VERSION ""

NS_ :

BS_:

BU_: APS EPS ESP MPC MRR SCM GW

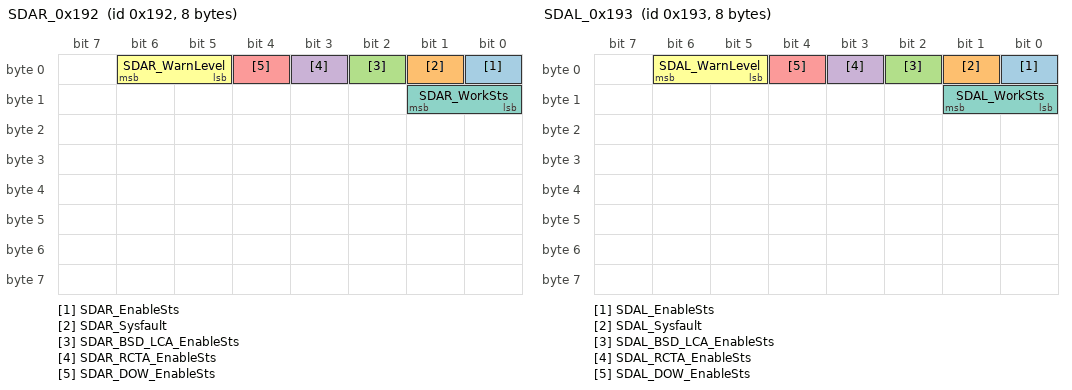
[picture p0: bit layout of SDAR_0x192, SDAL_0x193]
BO_ 402 SDAR_0x192: 8 GW
 SG_ SDAR_EnableSts : 0|1@0+ (1,0) [0|1] ""  APS
 SG_ SDAR_Sysfault : 1|1@0+ (1,0) [0|1] ""  APS
 SG_ SDAR_BSD_LCA_EnableSts : 2|1@0+ (1,0) [0|1] ""  APS
 SG_ SDAR_RCTA_EnableSts : 3|1@0+ (1,0) [0|1] ""  APS
 SG_ SDAR_DOW_EnableSts : 4|1@0+ (1,0) [0|1] ""  APS
 SG_ SDAR_WarnLevel : 6|2@0+ (1,0) [0|3] ""  APS
 SG_ SDAR_WorkSts : 9|2@0+ (1,0) [0|3] ""  APS

BO_ 403 SDAL_0x193: 8 GW
 SG_ SDAL_EnableSts : 0|1@0+ (1,0) [0|1] ""  APS
 SG_ SDAL_Sysfault : 1|1@0+ (1,0) [0|1] ""  APS
 SG_ SDAL_BSD_LCA_EnableSts : 2|1@0+ (1,0) [0|1] ""  APS
 SG_ SDAL_RCTA_EnableSts : 3|1@0+ (1,0) [0|1] ""  APS
 SG_ SDAL_DOW_EnableSts : 4|1@0+ (1,0) [0|1] ""  APS
 SG_ SDAL_WarnLevel : 6|2@0+ (1,0) [0|3] ""  APS
 SG_ SDAL_WorkSts : 9|2@0+ (1,0) [0|3] ""  APS

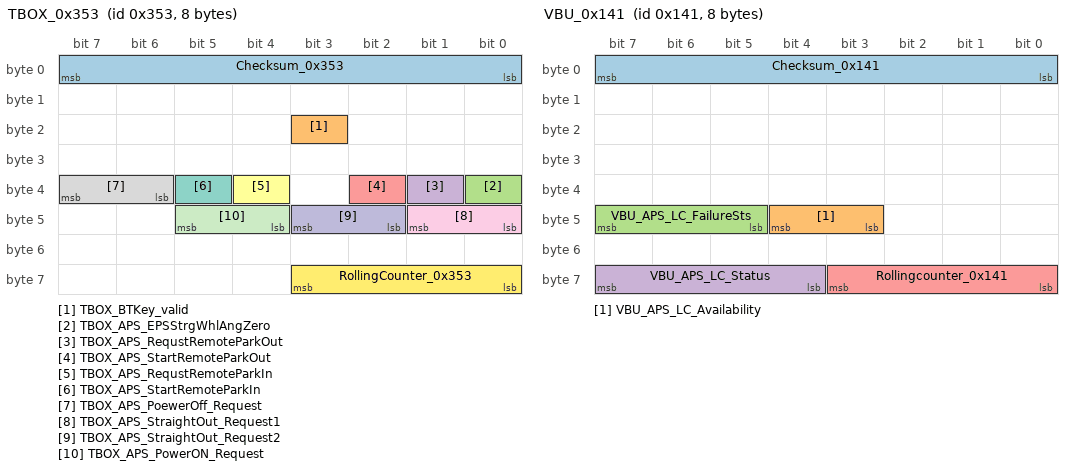
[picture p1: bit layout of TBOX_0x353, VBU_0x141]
BO_ 851 TBOX_0x353: 8 GW
 SG_ Checksum_0x353 : 7|8@0+ (1,0) [0|255] ""  APS
 SG_ TBOX_BTKey_valid : 19|1@0+ (1,0) [0|1] ""  APS
 SG_ TBOX_APS_EPSStrgWhlAngZero : 32|1@0+ (1,0) [0|1] ""  APS
 SG_ TBOX_APS_RequstRemoteParkOut : 33|1@0+ (1,0) [0|1] ""  APS
 SG_ TBOX_APS_StartRemoteParkOut : 34|1@0+ (1,0) [0|1] ""  APS
 SG_ TBOX_APS_RequstRemoteParkIn : 36|1@0+ (1,0) [0|1] ""  APS
 SG_ TBOX_APS_StartRemoteParkIn : 37|1@0+ (1,0) [0|1] ""  APS
 SG_ TBOX_APS_PoewerOff_Request : 39|2@0+ (1,0) [0|3] ""  APS
 SG_ TBOX_APS_StraightOut_Request1 : 41|2@0+ (1,0) [0|3] ""  APS
 SG_ TBOX_APS_StraightOut_Request2 : 43|2@0+ (1,0) [0|3] ""  APS
 SG_ TBOX_APS_PowerON_Request : 45|2@0+ (1,0) [0|3] ""  APS
 SG_ RollingCounter_0x353 : 59|4@0+ (1,0) [0|15] ""  APS

BO_ 289 ESP_0x121: 8 ESP
 SG_ Checksum_0x121 : 7|8@0+ (1,0) [0|255] ""  EPS,MPC,MRR,APS,GW
 SG_ ESP_VehicleSpeed : 11|12@0+ (0.05625,0) [0|230.2875] "kph"  EPS,MPC,MRR,APS,GW
 SG_ ESP_VehicleSpeed_Valid : 12|1@0+ (1,0) [0|1] ""  EPS,MPC,MRR,APS,GW
 SG_ ESP_ABS_Error : 14|1@0+ (1,0) [0|1] ""  EPS,MRR,APS,GW
 SG_ ESP_ABS_Intervention : 15|1@0+ (1,0) [0|1] ""  EPS,MPC,MRR,APS,GW
 SG_ ESP_VDC_TCS_Error : 24|1@0+ (1,0) [0|1] ""  MRR,APS,GW
 SG_ ESP_EBD_Error : 25|1@0+ (1,0) [0|1] ""  MRR,APS,GW
 SG_ ESP_VDC_Intervention : 26|1@0+ (1,0) [0|1] ""  MRR,APS,GW
 SG_ ESP_TCS_Intervention : 27|1@0+ (1,0) [0|1] ""  MRR,APS,GW
 SG_ ESP_EBD_Intervention : 28|1@0+ (1,0) [0|1] ""  MRR,APS,GW
 SG_ ESP_HDC_Available : 32|1@0+ (1,0) [0|1] ""  MRR,APS,GW
 SG_ ESP_EPBMainteDiagmodeActive : 33|1@0+ (1,0) [0|1] ""  MRR,APS,GW
 SG_ ESP_EPBStatus : 37|3@0+ (1,0) [0|7] ""  MRR,APS,GW
 SG_ ESP_VehicleStop : 38|1@0+ (1,0) [0|1] ""  MRR,APS,GW
 SG_ ESP_VehicleStop_Valid : 39|1@0+ (1,0) [0|1] ""  MRR,APS,GW
 SG_ ESP_WheelCyBrakeForce_Exist : 49|1@0+ (1,0) [0|1] ""  MRR,APS,GW
 SG_ ESP_HHC_Available : 54|1@0+ (1,0) [0|1] ""  APS,GW
 SG_ ESP_HHCActive : 55|1@0+ (1,0) [0|1] ""  APS,GW

BO_ 305 MRR_0x131: 8 MRR
 SG_ MRR_ACC_Status : 53|4@0+ (1,0) [0|15] ""  ESP,APS

BO_ 321 VBU_0x141: 8 GW
 SG_ Checksum_0x141 : 7|8@0+ (1,0) [0|255] ""  ESP,APS
 SG_ VBU_APS_LC_Availability : 44|2@0+ (1,0) [0|3] ""  APS
 SG_ VBU_APS_LC_FailureSts : 47|3@0+ (1,0) [0|7] ""  APS
 SG_ VBU_APS_LC_Status : 63|4@0+ (1,0) [0|15] ""  APS
 SG_ Rollingcounter_0x141 : 59|4@0+ (1,0) [0|15] ""  ESP,APS

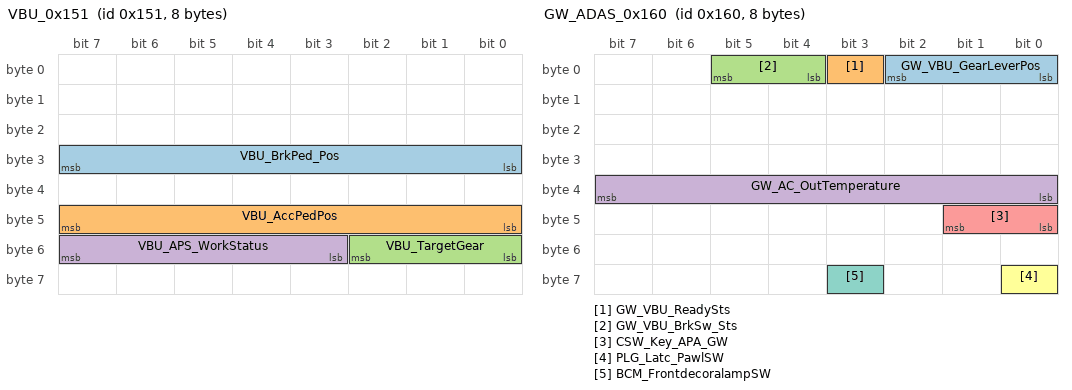
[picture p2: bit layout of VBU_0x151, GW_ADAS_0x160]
BO_ 337 VBU_0x151: 8 GW
 SG_ VBU_BrkPed_Pos : 31|8@0+ (1,0) [0|100] "%"  APS
 SG_ VBU_AccPedPos : 47|8@0+ (0.5,0) [0|100] "%"  ESP,MPC,MRR,APS
 SG_ VBU_TargetGear : 50|3@0+ (1,0) [0|7] ""  ESP,APS
 SG_ VBU_APS_WorkStatus : 55|5@0+ (1,0) [0|31] ""  APS

BO_ 341 GW_LIN_0x155: 8 GW
 SG_ SWS_L_360keyStatus : 11|2@0+ (1,0) [0|3] ""  APS

BO_ 352 GW_ADAS_0x160: 8 GW
 SG_ GW_VBU_GearLeverPos : 2|3@0+ (1,0) [0|7] ""  EPS,ESP,MPC,MRR,APS,SCM
 SG_ GW_VBU_ReadySts : 3|1@0+ (1,0) [0|1] ""  EPS,ESP,MPC,MRR,APS
 SG_ GW_VBU_BrkSw_Sts : 5|2@0+ (1,0) [0|3] ""  EPS,ESP,MPC,APS
 SG_ GW_AC_OutTemperature : 39|8@0+ (0.5,-40) [-40|80] "degC"  ESP,MPC,MRR,APS
 SG_ CSW_Key_APA_GW : 41|2@0+ (1,0) [0|3] ""  APS
 SG_ PLG_Latc_PawlSW : 56|1@0+ (1,0) [0|1] ""  APS
 SG_ BCM_FrontdecoralampSW : 59|1@0+ (1,0) [0|1] ""  APS

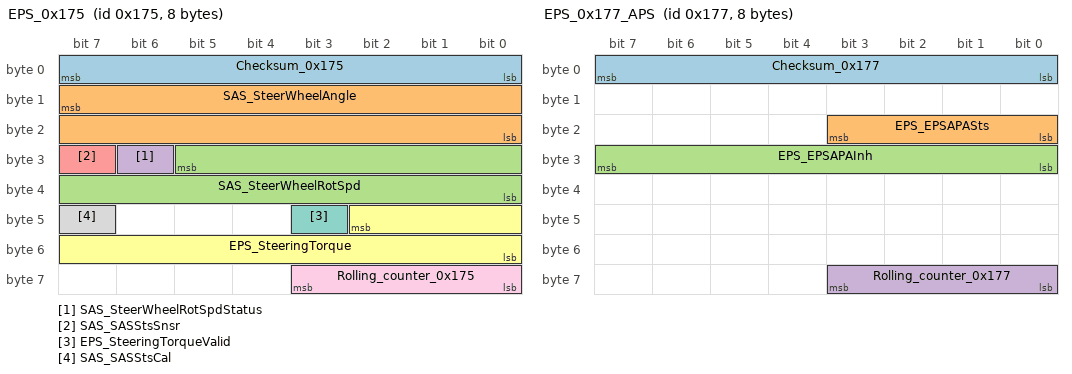
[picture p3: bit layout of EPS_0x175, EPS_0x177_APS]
BO_ 373 EPS_0x175: 8 EPS
 SG_ Checksum_0x175 : 7|8@0+ (1,0) [0|255] ""  ESP,MPC,MRR,APS,GW
 SG_ SAS_SteerWheelAngle : 15|16@0+ (0.0238,-780) [-780|779.733] "deg"  ESP,MPC,MRR,APS,GW
 SG_ SAS_SteerWheelRotSpd : 29|14@0+ (0.125,-1024) [-1024|1023.75] "degps"  MPC,MRR,APS,GW
 SG_ SAS_SteerWheelRotSpdStatus : 30|1@0+ (1,0) [0|1] ""  MPC,MRR,APS,GW
 SG_ SAS_SASStsSnsr : 31|1@0+ (1,0) [0|1] ""  ESP,MPC,MRR,APS,GW
 SG_ EPS_SteeringTorque : 42|11@0+ (0.01,-10.24) [-10.24|10.23] "Nm"  MPC,APS,GW
 SG_ EPS_SteeringTorqueValid : 43|1@0+ (1,0) [0|1] ""  MPC,APS,GW
 SG_ SAS_SASStsCal : 47|1@0+ (1,0) [0|1] ""  ESP,MPC,MRR,APS,GW
 SG_ Rolling_counter_0x175 : 59|4@0+ (1,0) [0|15] ""  ESP,MPC,MRR,APS,GW

BO_ 375 EPS_0x177_APS: 8 EPS
 SG_ Checksum_0x177 : 7|8@0+ (1,0) [0|255] ""  APS
 SG_ EPS_EPSAPASts : 19|4@0+ (1,0) [0|15] ""  APS
 SG_ EPS_EPSAPAInh : 31|8@0+ (1,0) [0|255] ""  APS
 SG_ Rolling_counter_0x177 : 59|4@0+ (1,0) [0|15] ""  APS

BO_ 401 APS_0x191: 8 APS
 SG_ Checksum_0x191 : 7|8@0+ (1,0) [0|255] ""  GW
 SG_ APS_SystemSts : 10|3@0+ (1,0) [0|7] ""  GW
 SG_ APS_Active : 11|1@0+ (1,0) [0|1] ""  MPC,MRR,GW
 SG_ APS_VBU_BrakeFunctionMode : 15|4@0+ (1,0) [0|15] ""  GW
 SG_ APS_VBU_Speed_Limitation : 23|6@0+ (0.8,0) [0|5] "kph"  GW
 SG_ APS_VBU_Target_Gear_Request : 26|3@0+ (1,0) [0|7] ""  GW
 SG_ APS_AVM_HU_CurrentSts : 29|3@0+ (1,0) [0|7] ""  GW
 SG_ APS_HU_ParkPrompttone : 30|1@0+ (1,0) [0|1] ""  GW
 SG_ APS_VBU_APAFailed : 31|1@0+ (1,0) [0|1] ""  GW
 SG_ APS_AVM_FactoryMode : 33|1@0+ (1,0) [0|1] ""  GW
 SG_ APS_TBOXConect_ParkInResp : 37|2@0+ (1,0) [0|3] ""  GW
 SG_ APS_VBU_FailureBrakeMode : 39|2@0+ (1,0) [0|3] ""  GW
 SG_ APS_VBU_Stop_Distance : 45|8@0+ (1,0) [0|255] ""  GW
 SG_ APS_R_Gear_RequestTips : 47|2@0+ (1,0) [0|3] ""  GW
 SG_ APS_VBU_Req_StraightOut : 48|1@0+ (1,0) [0|1] ""  GW
 SG_ APS_VBU_BrakeModeSts : 51|3@0+ (1,0) [0|7] ""  GW
 SG_ APS_VBU_Req_StraightCtrol : 53|2@0+ (1,0) [0|3] ""  GW
 SG_ RollingCounter_0x191 : 59|4@0+ (1,0) [0|15] ""  GW

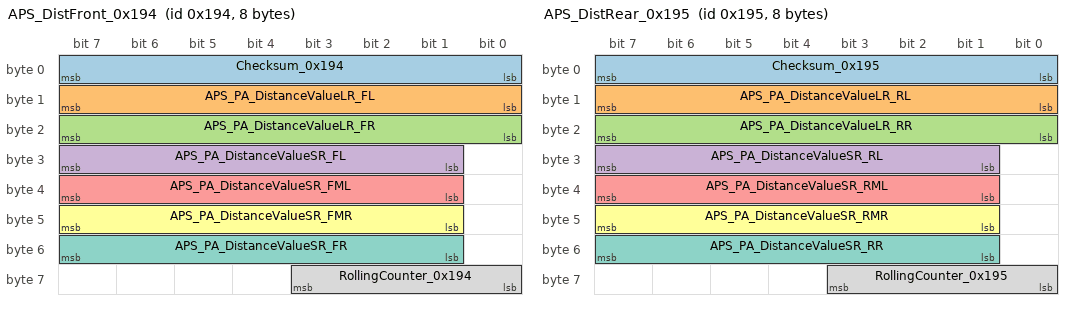
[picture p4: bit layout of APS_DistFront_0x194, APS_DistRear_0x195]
BO_ 404 APS_DistFront_0x194: 8 Vector__XXX
 SG_ Checksum_0x194 : 7|8@0+ (1,0) [0|255] "" Vector__XXX
 SG_ APS_PA_DistanceValueLR_FL : 15|8@0+ (2,0) [0|500] "cm" Vector__XXX
 SG_ APS_PA_DistanceValueLR_FR : 23|8@0+ (2,0) [0|500] "cm" Vector__XXX
 SG_ APS_PA_DistanceValueSR_FL : 31|7@0+ (2,0) [0|250] "cm" Vector__XXX
 SG_ APS_PA_DistanceValueSR_FML : 39|7@0+ (2,0) [0|250] "cm" Vector__XXX
 SG_ APS_PA_DistanceValueSR_FMR : 47|7@0+ (2,0) [0|250] "cm" Vector__XXX
 SG_ APS_PA_DistanceValueSR_FR : 55|7@0+ (2,0) [0|250] "cm" Vector__XXX
 SG_ RollingCounter_0x194 : 59|4@0+ (1,0) [0|15] "" Vector__XXX

BO_ 405 APS_DistRear_0x195: 8 Vector__XXX
 SG_ Checksum_0x195 : 7|8@0+ (1,0) [0|255] "" Vector__XXX
 SG_ APS_PA_DistanceValueLR_RL : 15|8@0+ (2,0) [0|500] "cm" Vector__XXX
 SG_ APS_PA_DistanceValueLR_RR : 23|8@0+ (2,0) [0|500] "cm" Vector__XXX
 SG_ APS_PA_DistanceValueSR_RL : 31|7@0+ (2,0) [0|250] "cm" Vector__XXX
 SG_ APS_PA_DistanceValueSR_RML : 39|7@0+ (2,0) [0|250] "cm" Vector__XXX
 SG_ APS_PA_DistanceValueSR_RMR : 47|7@0+ (2,0) [0|250] "cm" Vector__XXX
 SG_ APS_PA_DistanceValueSR_RR : 55|7@0+ (2,0) [0|250] "cm" Vector__XXX
 SG_ RollingCounter_0x195 : 59|4@0+ (1,0) [0|15] "" Vector__XXX

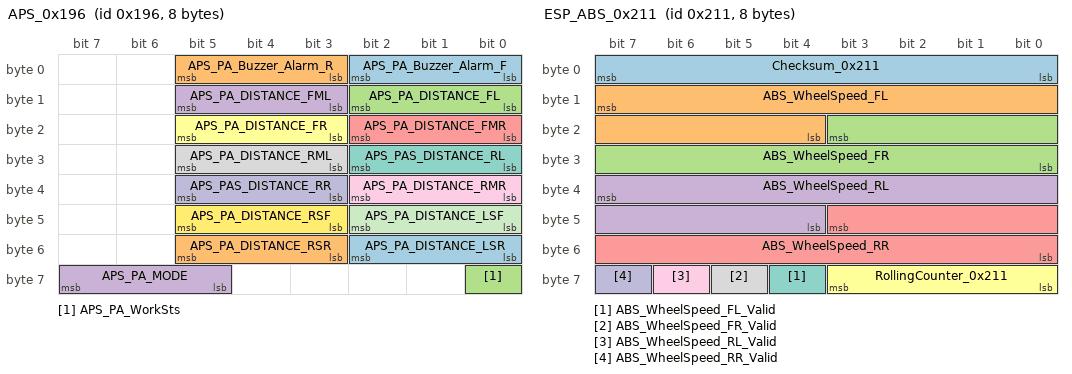
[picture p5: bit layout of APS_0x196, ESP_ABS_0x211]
BO_ 406 APS_0x196: 8 Vector__XXX
 SG_ APS_PA_Buzzer_Alarm_F : 2|3@0+ (1,0) [0|7] ""  GW
 SG_ APS_PA_Buzzer_Alarm_R : 5|3@0+ (1,0) [0|7] ""  GW
 SG_ APS_PA_DISTANCE_FL : 10|3@0+ (1,0) [0|7] ""  GW
 SG_ APS_PA_DISTANCE_FML : 13|3@0+ (1,0) [0|7] ""  GW
 SG_ APS_PA_DISTANCE_FMR : 18|3@0+ (1,0) [0|7] ""  GW
 SG_ APS_PA_DISTANCE_FR : 21|3@0+ (1,0) [0|7] ""  GW
 SG_ APS_PAS_DISTANCE_RL : 26|3@0+ (1,0) [0|7] ""  GW
 SG_ APS_PA_DISTANCE_RML : 29|3@0+ (1,0) [0|7] ""  GW
 SG_ APS_PA_DISTANCE_RMR : 34|3@0+ (1,0) [0|7] ""  GW
 SG_ APS_PAS_DISTANCE_RR : 37|3@0+ (1,0) [0|7] ""  GW
 SG_ APS_PA_DISTANCE_LSF : 42|3@0+ (1,0) [0|7] ""  GW
 SG_ APS_PA_DISTANCE_RSF : 45|3@0+ (1,0) [0|7] ""  GW
 SG_ APS_PA_DISTANCE_LSR : 50|3@0+ (1,0) [0|7] ""  GW
 SG_ APS_PA_DISTANCE_RSR : 53|3@0+ (1,0) [0|7] ""  GW
 SG_ APS_PA_WorkSts : 56|1@0+ (1,0) [0|1] ""  GW
 SG_ APS_PA_MODE : 63|3@0+ (1,0) [0|7] ""  GW

BO_ 529 ESP_ABS_0x211: 8 ESP
 SG_ Checksum_0x211 : 7|8@0+ (1,0) [0|255] ""  EPS,MRR,APS
 SG_ ABS_WheelSpeed_FL : 15|12@0+ (0.05625,0) [0|230.2875] "kph"  EPS,MRR,APS
 SG_ ABS_WheelSpeed_FR : 19|12@0+ (0.05625,0) [0|230.2875] "kph"  EPS,MRR,APS
 SG_ ABS_WheelSpeed_RL : 39|12@0+ (0.05625,0) [0|230.2875] "kph"  EPS,MRR,APS
 SG_ ABS_WheelSpeed_RR : 43|12@0+ (0.05625,0) [0|230.2875] "kph"  EPS,MRR,APS
 SG_ RollingCounter_0x211 : 59|4@0+ (1,0) [0|15] ""  EPS,MRR,APS
 SG_ ABS_WheelSpeed_FL_Valid : 60|1@0+ (1,0) [0|1] ""  EPS,MRR,APS
 SG_ ABS_WheelSpeed_FR_Valid : 61|1@0+ (1,0) [0|1] ""  EPS,MRR,APS
 SG_ ABS_WheelSpeed_RL_Valid : 62|1@0+ (1,0) [0|1] ""  EPS,MRR,APS
 SG_ ABS_WheelSpeed_RR_Valid : 63|1@0+ (1,0) [0|1] ""  EPS,MRR,APS

BO_ 532 ESP_0x214: 8 ESP
 SG_ Checksum_0x214 : 7|8@0+ (1,0) [0|255] ""  MRR,APS
 SG_ ESP_WheelDirection_FL : 9|2@0+ (1,0) [0|3] ""  MRR,APS
 SG_ ESP_WheelDirection_FL_Valid : 10|1@0+ (1,0) [0|1] ""  MRR,APS
 SG_ ESP_WheelDirection_FR : 12|2@0+ (1,0) [0|3] ""  MRR,APS
 SG_ ESP_WheelDirection_FR_Valid : 13|1@0+ (1,0) [0|1] ""  MRR,APS
 SG_ ESP_WheelDirection_RL : 15|2@0+ (1,0) [0|3] ""  MRR,APS
 SG_ ESP_WheelDirection_RL_Valid : 16|1@0+ (1,0) [0|1] ""  MRR,APS
 SG_ ESP_WheelDirection_RR : 18|2@0+ (1,0) [0|3] ""  MRR,APS
 SG_ ESP_WheelDirection_RR_Valid : 19|1@0+ (1,0) [0|1] ""  MRR,APS
 SG_ ESP_CDD_Intervention : 20|1@0+ (1,0) [0|1] ""  MRR,APS
 SG_ ESP_CDD_Available : 21|1@0+ (1,0) [0|1] ""  MRR,APS
 SG_ ESP_CDD_Error : 22|1@0+ (1,0) [0|1] ""  MRR,APS
 SG_ ESP_CDDTempOff : 23|1@0+ (1,0) [0|1] ""  MRR,APS
 SG_ ESP_VLC_EngTrqReq : 46|15@0+ (0.1,-1000) [-1000|1000] "Nm"  APS
 SG_ ESP_VLC_EngTrqReqActive : 47|1@0+ (1,0) [0|1] ""  APS
 SG_ RollingCounter_0x214 : 59|4@0+ (1,0) [0|15] ""  MRR,APS
 SG_ ESP_VLC_Intervention : 60|1@0+ (1,0) [0|1] ""  MRR,APS
 SG_ ESP_VLC_Error : 61|1@0+ (1,0) [0|1] ""  MRR,APS
 SG_ ESP_VLC_Available : 62|1@0+ (1,0) [0|1] ""  MRR,APS

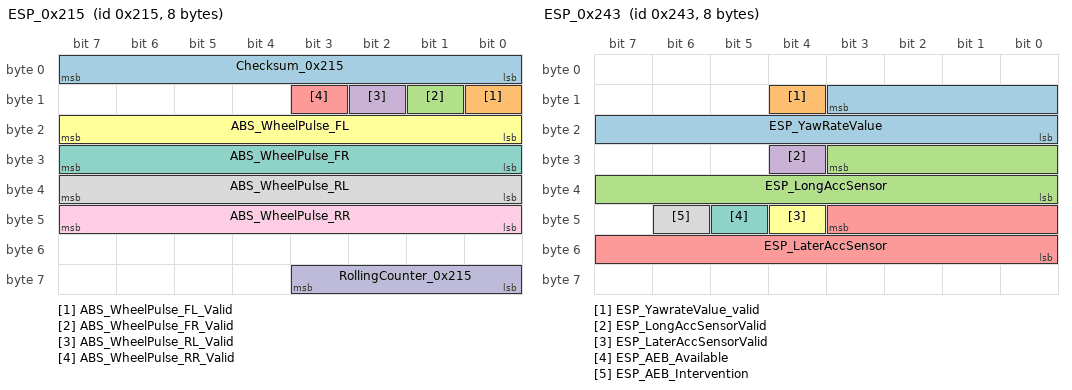
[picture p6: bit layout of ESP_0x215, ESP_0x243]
BO_ 533 ESP_0x215: 8 ESP
 SG_ Checksum_0x215 : 7|8@0+ (1,0) [0|255] ""  APS
 SG_ ABS_WheelPulse_FL_Valid : 8|1@0+ (1,0) [0|1] ""  APS
 SG_ ABS_WheelPulse_FR_Valid : 9|1@0+ (1,0) [0|1] ""  APS
 SG_ ABS_WheelPulse_RL_Valid : 10|1@0+ (1,0) [0|1] ""  APS
 SG_ ABS_WheelPulse_RR_Valid : 11|1@0+ (1,0) [0|1] ""  APS
 SG_ ABS_WheelPulse_FL : 23|8@0+ (1,0) [0|255] ""  APS
 SG_ ABS_WheelPulse_FR : 31|8@0+ (1,0) [0|255] ""  APS
 SG_ ABS_WheelPulse_RL : 39|8@0+ (1,0) [0|255] ""  APS
 SG_ ABS_WheelPulse_RR : 47|8@0+ (1,0) [0|255] ""  APS
 SG_ RollingCounter_0x215 : 59|4@0+ (1,0) [0|15] ""  APS

BO_ 579 ESP_0x243: 8 ESP
 SG_ ESP_YawRateValue : 11|12@0+ (0.05,-75) [-75|75] "deg"  MPC,MRR,APS,GW
 SG_ ESP_YawrateValue_valid : 12|1@0+ (1,0) [0|1] ""  MPC,MRR,APS,GW
 SG_ ESP_LongAccSensor : 27|12@0+ (0.01,-20) [-20|20] "mps2"  MPC,MRR,APS,GW
 SG_ ESP_LongAccSensorValid : 28|1@0+ (1,0) [0|1] ""  MPC,MRR,APS,GW
 SG_ ESP_LaterAccSensor : 43|12@0+ (0.01,-20) [-20|20] "mps2"  MPC,MRR,APS,GW
 SG_ ESP_LaterAccSensorValid : 44|1@0+ (1,0) [0|1] ""  MPC,MRR,APS,GW
 SG_ ESP_AEB_Available : 45|1@0+ (1,0) [0|1] ""  MRR,APS,GW
 SG_ ESP_AEB_Intervention : 46|1@0+ (1,0) [0|1] ""  MRR,APS,GW

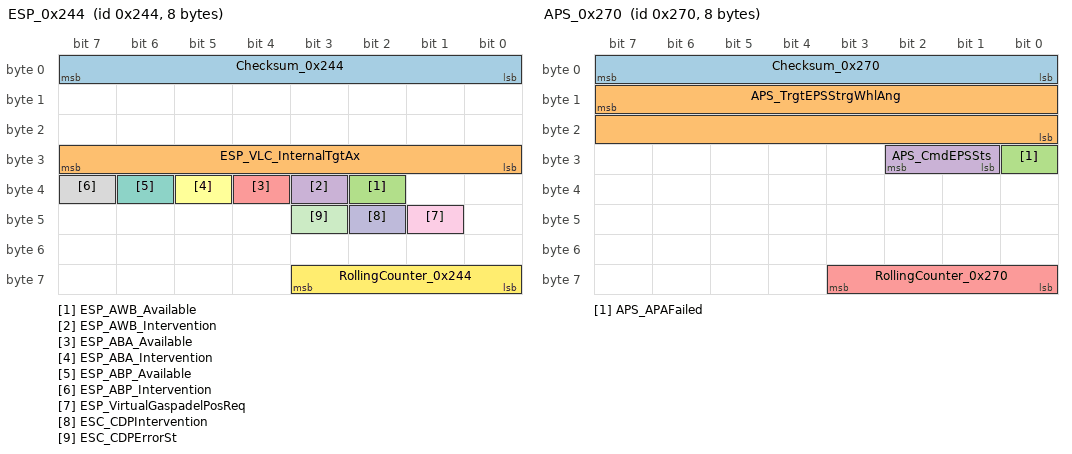
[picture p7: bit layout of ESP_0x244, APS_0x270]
BO_ 580 ESP_0x244: 8 ESP
 SG_ Checksum_0x244 : 7|8@0+ (1,0) [0|255] ""  MRR,APS
 SG_ ESP_VLC_InternalTgtAx : 31|8@0+ (0.05,-7) [-7|5.75] "mps2"  MRR,APS
 SG_ ESP_AWB_Available : 34|1@0+ (1,0) [0|1] ""  MRR,APS
 SG_ ESP_AWB_Intervention : 35|1@0+ (1,0) [0|1] ""  MRR,APS
 SG_ ESP_ABA_Available : 36|1@0+ (1,0) [0|1] ""  MRR,APS
 SG_ ESP_ABA_Intervention : 37|1@0+ (1,0) [0|1] ""  MRR,APS
 SG_ ESP_ABP_Available : 38|1@0+ (1,0) [0|1] ""  MRR,APS
 SG_ ESP_ABP_Intervention : 39|1@0+ (1,0) [0|1] ""  MRR,APS
 SG_ ESP_VirtualGaspadelPosReq : 41|1@0+ (1,0) [0|1] ""  APS
 SG_ ESC_CDPIntervention : 42|1@0+ (1,0) [0|1] ""  MRR,APS
 SG_ ESC_CDPErrorSt : 43|1@0+ (1,0) [0|1] ""  APS
 SG_ RollingCounter_0x244 : 59|4@0+ (1,0) [0|15] ""  MRR,APS

BO_ 624 APS_0x270: 8 APS
 SG_ Checksum_0x270 : 7|8@0+ (1,0) [0|255] ""  EPS
 SG_ APS_TrgtEPSStrgWhlAng : 15|16@0+ (0.0238,-780) [-780|779.733] "deg"  EPS
 SG_ APS_APAFailed : 24|1@0+ (1,0) [0|1] ""  EPS
 SG_ APS_CmdEPSSts : 26|2@0+ (1,0) [0|3] ""  EPS
 SG_ RollingCounter_0x270 : 59|4@0+ (1,0) [0|15] ""  EPS

BO_ 625 APS_0x271: 8 APS
 SG_ Checksum_0x271 : 7|8@0+ (1,0) [0|255] ""  GW
 SG_ APS_AutoSearchSts : 10|3@0+ (1,0) [0|7] ""  GW
 SG_ APS_ParkOutChkResult : 11|1@0+ (1,0) [0|1] ""  GW
 SG_ APS_CurrentPathNum : 15|4@0+ (1,0) [0|15] ""  GW
 SG_ APS_TotalPathNum : 19|4@0+ (1,0) [0|15] ""  GW
 SG_ APS_SuspendedReason : 22|3@0+ (1,0) [0|7] ""  GW
 SG_ APS_AbortReason : 28|5@0+ (1,0) [0|31] ""  GW
 SG_ APS_CurrentParkType : 31|3@0+ (1,0) [0|7] ""  GW
 SG_ APS_OverrideReason : 34|3@0+ (1,0) [0|7] ""  GW
 SG_ APS_VehicleDirection : 36|2@0+ (1,0) [0|3] ""  GW
 SG_ APS_TerminatedType : 38|2@0+ (1,0) [0|3] ""  GW
 SG_ APS_ParkOutSystemStatus : 39|1@0+ (1,0) [0|1] ""  GW
 SG_ APS_CurrentStepNum : 43|4@0+ (1,0) [0|15] ""  GW
 SG_ APS_RemoteParkIn_Status : 46|3@0+ (1,0) [0|7] ""  GW
 SG_ APS_RemoteParkInResp : 47|1@0+ (1,0) [0|1] ""  GW
 SG_ APS_BCM_RemoteParkIn_Status : 48|1@0+ (1,0) [0|1] ""  GW
 SG_ APS_BCM_DoubleFlash : 49|1@0+ (1,0) [0|1] ""  GW
 SG_ APS_BCM_AllDoorUnLock_Door : 50|1@0+ (1,0) [0|1] ""  GW
 SG_ APS_RemoteParkOutResp : 51|1@0+ (1,0) [0|1] ""  GW
 SG_ APS_BCM_PowerOffReq : 52|1@0+ (1,0) [0|1] ""  GW
 SG_ APS_RemotePark_Error_Status : 55|3@0+ (1,0) [0|7] ""  GW
 SG_ RollingCounter_0x271 : 59|4@0+ (1,0) [0|15] ""  GW

BO_ 642 SCM_0x282: 8 SCM
 SG_ SCM_PRND_req : 34|3@0+ (1,0) [0|7] ""  APS,GW

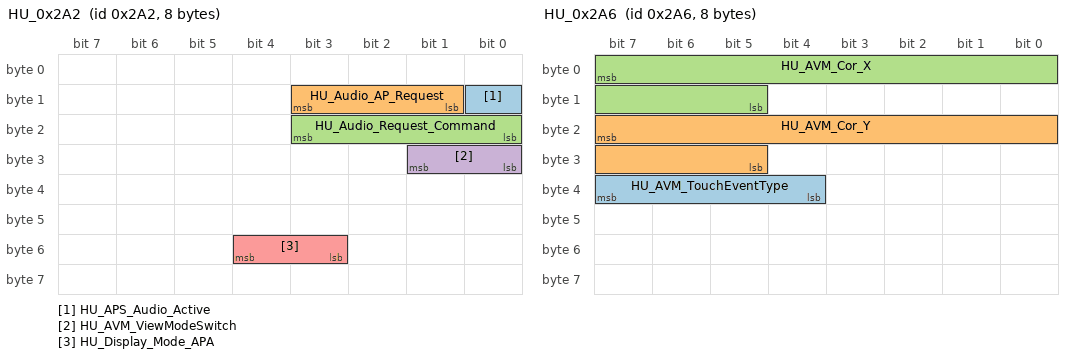
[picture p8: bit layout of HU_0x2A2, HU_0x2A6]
BO_ 674 HU_0x2A2: 8 GW
 SG_ HU_APS_Audio_Active : 8|1@0+ (1,0) [0|1] ""  APS
 SG_ HU_Audio_AP_Request : 11|3@0+ (1,0) [0|7] ""  APS
 SG_ HU_Audio_Request_Command : 19|4@0+ (1,0) [0|15] ""  APS
 SG_ HU_AVM_ViewModeSwitch : 25|2@0+ (1,0) [0|3] ""  APS
 SG_ HU_Display_Mode_APA : 52|2@0+ (1,0) [0|3] ""  APS

BO_ 678 HU_0x2A6: 8 GW
 SG_ HU_AVM_TouchEventType : 39|4@0+ (1,0) [0|15] ""  APS
 SG_ HU_AVM_Cor_Y : 23|11@0+ (1,0) [0|2047] ""  APS
 SG_ HU_AVM_Cor_X : 7|11@0+ (1,0) [0|2047] ""  APS

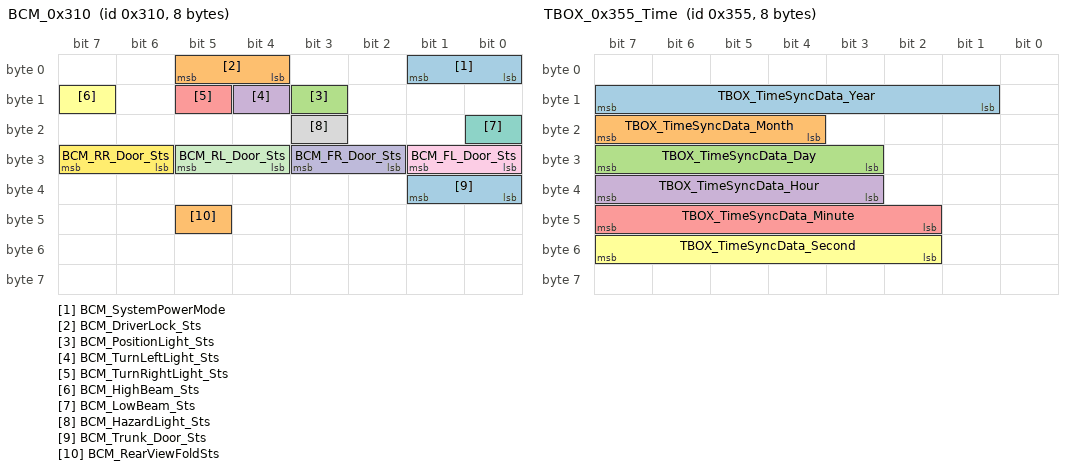
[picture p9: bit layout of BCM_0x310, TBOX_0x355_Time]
BO_ 784 BCM_0x310: 8 GW
 SG_ BCM_SystemPowerMode : 1|2@0+ (1,0) [0|3] ""  ESP,MPC,MRR,APS
 SG_ BCM_DriverLock_Sts : 5|2@0+ (1,0) [0|3] ""  APS
 SG_ BCM_PositionLight_Sts : 11|1@0+ (1,0) [0|1] ""  APS
 SG_ BCM_TurnLeftLight_Sts : 12|1@0+ (1,0) [0|1] ""  MPC,APS
 SG_ BCM_TurnRightLight_Sts : 13|1@0+ (1,0) [0|1] ""  MPC,APS
 SG_ BCM_HighBeam_Sts : 15|1@0+ (1,0) [0|1] ""  MPC,APS
 SG_ BCM_LowBeam_Sts : 16|1@0+ (1,0) [0|1] ""  MPC,APS
 SG_ BCM_HazardLight_Sts : 19|1@0+ (1,0) [0|1] ""  MPC,APS
 SG_ BCM_FL_Door_Sts : 25|2@0+ (1,0) [0|3] ""  ESP,MRR,APS
 SG_ BCM_FR_Door_Sts : 27|2@0+ (1,0) [0|3] ""  MRR,APS
 SG_ BCM_RL_Door_Sts : 29|2@0+ (1,0) [0|3] ""  MRR,APS
 SG_ BCM_RR_Door_Sts : 31|2@0+ (1,0) [0|3] ""  MRR,APS
 SG_ BCM_Trunk_Door_Sts : 33|2@0+ (1,0) [0|3] ""  APS
 SG_ BCM_RearViewFoldSts : 45|1@0+ (1,0) [0|1] ""  APS

BO_ 853 TBOX_0x355_Time: 8 GW
 SG_ TBOX_TimeSyncData_Year : 15|7@0+ (1,2000) [2000|2099] ""  EPS,ESP,MPC,MRR,APS
 SG_ TBOX_TimeSyncData_Month : 23|4@0+ (1,0) [1|12] ""  EPS,ESP,MPC,MRR,APS
 SG_ TBOX_TimeSyncData_Day : 31|5@0+ (1,0) [1|31] ""  EPS,ESP,MPC,MRR,APS
 SG_ TBOX_TimeSyncData_Hour : 39|5@0+ (1,0) [0|23] ""  EPS,ESP,MPC,MRR,APS
 SG_ TBOX_TimeSyncData_Minute : 47|6@0+ (1,0) [0|59] ""  EPS,ESP,MPC,MRR,APS
 SG_ TBOX_TimeSyncData_Second : 55|6@0+ (1,0) [0|59] ""  EPS,ESP,MPC,MRR,APS

BO_ 928 ICM_0x3A0: 8 GW
 SG_ ICM_DisPlayVehicleSpeed : 27|12@0+ (0.05625,0) [0|230.2875] "kph"  MPC,MRR,APS

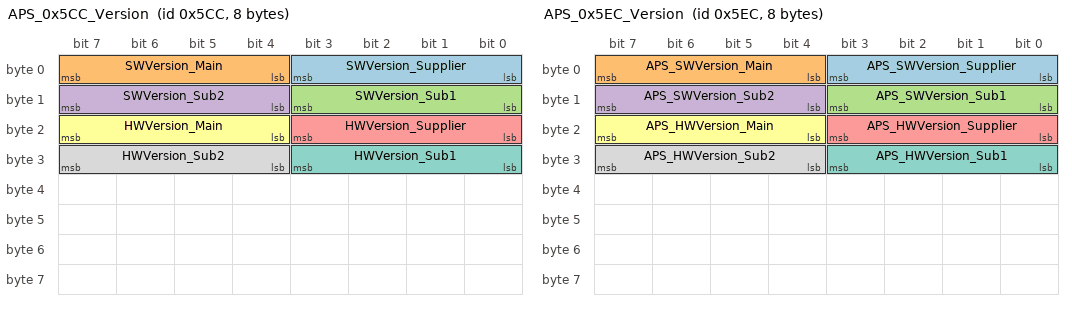
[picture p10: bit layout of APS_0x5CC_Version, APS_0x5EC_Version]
BO_ 1484 APS_0x5CC_Version: 8 Vector__XXX
 SG_ SWVersion_Supplier : 3|4@0+ (1,0) [0|15] ""  GW
 SG_ SWVersion_Main : 7|4@0+ (1,0) [0|15] ""  GW
 SG_ SWVersion_Sub1 : 11|4@0+ (1,0) [0|15] ""  GW
 SG_ SWVersion_Sub2 : 15|4@0+ (1,0) [0|15] ""  GW
 SG_ HWVersion_Supplier : 19|4@0+ (1,0) [0|15] ""  GW
 SG_ HWVersion_Main : 23|4@0+ (1,0) [0|15] ""  GW
 SG_ HWVersion_Sub1 : 27|4@0+ (1,0) [0|15] ""  GW
 SG_ HWVersion_Sub2 : 31|4@0+ (1,0) [0|15] ""  GW

BO_ 1516 APS_0x5EC_Version: 8 APS
 SG_ APS_SWVersion_Supplier : 3|4@0+ (1,0) [0|15] ""  GW
 SG_ APS_SWVersion_Main : 7|4@0+ (1,0) [0|15] ""  GW
 SG_ APS_SWVersion_Sub1 : 11|4@0+ (1,0) [0|15] ""  GW
 SG_ APS_SWVersion_Sub2 : 15|4@0+ (1,0) [0|15] ""  GW
 SG_ APS_HWVersion_Supplier : 19|4@0+ (1,0) [0|15] ""  GW
 SG_ APS_HWVersion_Main : 23|4@0+ (1,0) [0|15] ""  GW
 SG_ APS_HWVersion_Sub1 : 27|4@0+ (1,0) [0|15] ""  GW
 SG_ APS_HWVersion_Sub2 : 31|4@0+ (1,0) [0|15] ""  GW

BO_ 1829 APS_UDSDiag_ReqPhsy: 8 GW
 SG_ APS_UDSDiag_ReqPhsy_0x725 : 7|64@0+ (1,0) [0|255] "" Vector__XXX

BO_ 1837 APS_UDSDiag_Resp: 8 Vector__XXX
 SG_ APS_UDSDiag_Resp_0x72D : 7|64@0+ (1,0) [0|255] ""  GW

BO_ 2015 UDSDiag_ReqFunc: 8 GW
 SG_ UDSDiag_ReqFunc_0x7DF : 7|64@0+ (1,0) [0|255] ""  EPS,ESP,MPC,MRR,SCM

BO_ 1841 PA_UDSDiag_ReqPhsy: 8 GW
 SG_ PA_UDSDiag_ReqPhsy_0x731 : 7|64@0+ (1,0) [0|255] "" Vector__XXX

BO_ 1849 PA_UDSDiag_Resp: 8 Vector__XXX
 SG_ PA_UDSDiag_Resp_0x739 : 7|64@0+ (1,0) [0|255] ""  GW

CM_ SG_ 402 SDAR_EnableSts "右雷达使能状态";
CM_ SG_ 402 SDAR_Sysfault "右雷达系统错误";
CM_ SG_ 402 SDAR_BSD_LCA_EnableSts "BSD/LCA功能使能状态";
CM_ SG_ 402 SDAR_RCTA_EnableSts "RCTA功能使能状态";
CM_ SG_ 402 SDAR_DOW_EnableSts "DOW功能使能状态";
CM_ SG_ 402 SDAR_WarnLevel "右雷达报警等级";
CM_ SG_ 402 SDAR_WorkSts "右雷达工作状态";
CM_ SG_ 403 SDAL_EnableSts "左雷达使能状态";
CM_ SG_ 403 SDAL_Sysfault "左雷达系统错误";
CM_ SG_ 403 SDAL_BSD_LCA_EnableSts "BSD/LCA功能使能状态";
CM_ SG_ 403 SDAL_RCTA_EnableSts "RCTA功能使能状态";
CM_ SG_ 403 SDAL_DOW_EnableSts "DOW功能使能状态";
CM_ SG_ 403 SDAL_WarnLevel "左雷达报警等级";
CM_ SG_ 403 SDAL_WorkSts "左雷达工作状态";
CM_ SG_ 851 Checksum_0x353 "Checksum: IDMSB XOR IDLSB XOR Byte1 XOR Byte2 XOR Byte3 XOR Byte4 XOR Byte5 XOR Byte6 XOR Byte7";
CM_ SG_ 851 TBOX_BTKey_valid "TBOX蓝牙钥匙连接状态";
CM_ SG_ 851 TBOX_APS_EPSStrgWhlAngZero "一键回正方向盘信号";
CM_ SG_ 851 TBOX_APS_RequstRemoteParkOut "TBOX允许遥控泊出指令";
CM_ SG_ 851 TBOX_APS_StartRemoteParkOut "按下APP遥控泊出按键状态";
CM_ SG_ 851 TBOX_APS_RequstRemoteParkIn "TBOX允许遥控泊入指令";
CM_ SG_ 851 TBOX_APS_StartRemoteParkIn "按下APP遥控泊入按键状态";
CM_ SG_ 851 TBOX_APS_PoewerOff_Request "TBOX请求APS下电";
CM_ SG_ 851 TBOX_APS_StraightOut_Request1 "TBOX请求APS执行左转、右转";
CM_ SG_ 851 TBOX_APS_StraightOut_Request2 "TBOX请求APS执行前进、后退";
CM_ SG_ 851 TBOX_APS_PowerON_Request "上电请求，发给APA
(无控制请求时，发送0x0。当激活控制命令时，发送0x1/0x2/0x3。连续发送5次，之后将控制信号重新置0x0)";
CM_ SG_ 851 RollingCounter_0x353 "RollingCounter: used 4bit length signal and the arithmetic is increased from 0 to 15 by every message.";
CM_ SG_ 289 Checksum_0x121 "Checksum: IDMSB XOR IDLSB XOR Byte1 XOR Byte2 XOR Byte3 XOR Byte4 XOR Byte5 XOR Byte6 XOR Byte7";
CM_ SG_ 289 ESP_VehicleSpeed "Current Vehicle Speed
当前实际车速";
CM_ SG_ 289 ESP_VehicleSpeed_Valid "Vehicle speed value valid
车速有效";
CM_ SG_ 289 ESP_ABS_Error "ABS_Fault: ESP system has detected a failure which does not allow a reliable ABS regulation and is therefore switched off";
CM_ SG_ 289 ESP_ABS_Intervention "ABS control active - Indication that ESP system (especially ABS module) currently performs a brake intervention";
CM_ SG_ 289 ESP_VDC_TCS_Error "ESP_Fault: VDC/TCS is switched off due to detected failure";
CM_ SG_ 289 ESP_EBD_Error "EBD_Fault: ESP system has detected a heavy fault, which does not even allow a reliable electronic brake distribution and is therefore completely shut down";
CM_ SG_ 289 ESP_VDC_Intervention "VDC controller active: Oversteering brake intervention or Understeering brake intervention";
CM_ SG_ 289 ESP_TCS_Intervention "TCS controller active: Brake intervention or Engine torque reduction intervention";
CM_ SG_ 289 ESP_EBD_Intervention "EBD control active - Indication that ESP system (especially EBD module) currently performs a brake intervention";
CM_ SG_ 289 ESP_HDC_Available "HMI Responsible,CAN get degrateHDC statement from DSW and send out";
CM_ SG_ 289 ESP_EPBMainteDiagmodeActive "EPB Maintenance diagnosis mode status";
CM_ SG_ 289 ESP_EPBStatus "Indicating the status of EPB";
CM_ SG_ 289 ESP_VehicleStop "Indicates if vehicle is in standstill (if more or equal to two wheels are standstill).
Set to a desired state when standstill is surely reached.
";
CM_ SG_ 289 ESP_VehicleStop_Valid "Check the validity of the signal of VehicleStop.";
CM_ SG_ 289 ESP_WheelCyBrakeForce_Exist "No brake pressure applied; Generally it indicates wheel cylinder presure.";
CM_ SG_ 289 ESP_HHC_Available "HHC  is available or not";
CM_ SG_ 289 ESP_HHCActive "Indicates HHCH in active or not ";
CM_ SG_ 305 MRR_ACC_Status "The status of the ACC control unit.
The ACC mode should be contained in every message sent by ACC.";
CM_ SG_ 321 Checksum_0x141 "Checksum: IDMSB XOR IDLSB XOR Byte1 XOR Byte2 XOR Byte3 XOR Byte4 XOR Byte5 XOR Byte6 XOR Byte7";
CM_ SG_ 321 VBU_APS_LC_Availability "VBU_APS_LC_Availability";
CM_ SG_ 321 VBU_APS_LC_FailureSts "VBU_APS_LC_FailureSts";
CM_ SG_ 321 VBU_APS_LC_Status "VBU_APS_LC_Status";
CM_ SG_ 321 Rollingcounter_0x141 "从0到15循环计数，如果通信中断，则重新从0开始计数。";
CM_ SG_ 337 VBU_BrkPed_Pos "制动踏板位置度信号
0x64-0xFF:Invalid";
CM_ SG_ 337 VBU_AccPedPos "油门踏板位置度
Accelerator pedal position
0xC8-0xFF:Invalid";
CM_ SG_ 337 VBU_TargetGear "VBU target gear";
CM_ SG_ 337 VBU_APS_WorkStatus "VBU反馈给APS的工作状态";
CM_ SG_ 341 SWS_L_360keyStatus "左方向盘360摄像头（高配）/倒车影像（低配）的按键动作";
CM_ SG_ 352 GW_VBU_GearLeverPos "当前实际档位
vehicle Current Gear position";
CM_ SG_ 352 GW_VBU_ReadySts "纯电动车Ready信号
vehicle Ready Status ";
CM_ SG_ 352 GW_VBU_BrkSw_Sts "制动踏板开关状态
Brake pedal switch Status";
CM_ SG_ 352 GW_AC_OutTemperature "车外温度";
CM_ SG_ 352 CSW_Key_APA_GW "APA按钮状态（高配）";
CM_ SG_ 352 PLG_Latc_PawlSW "后背门锁（一级锁位）开关状态，后背门开关状态";
CM_ SG_ 352 BCM_FrontdecoralampSW "前部装饰灯状态";
CM_ SG_ 373 Checksum_0x175 "Checksum: IDMSB XOR IDLSB XOR Byte1 XOR Byte2 XOR Byte3 XOR Byte4 XOR Byte5 XOR Byte6 XOR Byte7";
CM_ SG_ 373 SAS_SteerWheelAngle "The current angle of the steering wheel（Positive, to left; Negative, to right）
转向角度，左正右负";
CM_ SG_ 373 SAS_SteerWheelRotSpd "The current rotation speed of the steering wheel.
转向角速度";
CM_ SG_ 373 SAS_SteerWheelRotSpdStatus "The status of SteerWheelRotSpd
转向角速度有效性";
CM_ SG_ 373 SAS_SASStsSnsr "the flag of  SAS status
Punch:Steering angle status
SAS硬件故障状态";
CM_ SG_ 373 EPS_SteeringTorque "施加在方向盘上的驾驶员手力矩，左正右负
Driver steering torque，left+/right-";
CM_ SG_ 373 EPS_SteeringTorqueValid "Validation bit of torsion bar torque";
CM_ SG_ 373 SAS_SASStsCal "The calibration status of SAS
传感器标定状态";
CM_ SG_ 373 Rolling_counter_0x175 "RollingCounter: used 4bit length signal and the arithmetic is increased from 0 to 15 by every message.";
CM_ SG_ 375 Checksum_0x177 "Checksum: IDMSB XOR IDLSB XOR Byte1 XOR Byte2 XOR Byte3 XOR Byte4 XOR Byte5 XOR Byte6XOR Byte7";
CM_ SG_ 375 EPS_EPSAPASts "Electric Power Steering Advanced Park Assist Status ，maximum signal value is 0xF but Signal Value Description is available only for 0 to 7 ，others Reserved，当EPS_EPSAPASts=active时自动泊车允许控制转向";
CM_ SG_ 375 EPS_EPSAPAInh "Electric Power Steering Advanced Park Assist Inhibit。maximum signal value is 0xFF but Signal Value Description is available only for 0,1,2,4,8 and 10，others Reserved";
CM_ SG_ 375 Rolling_counter_0x177 "RollingCounter: used 4bit length signal and the arithmetic is increased from 0 to 15 by every message.";
CM_ SG_ 401 Checksum_0x191 "Checksum: IDMSB XOR IDLSB XOR Byte1 XOR Byte2 XOR Byte3 XOR Byte4 XOR Byte5 XOR Byte6 XOR Byte7";
CM_ SG_ 401 APS_SystemSts "APA功能内部状态
";
CM_ SG_ 401 APS_Active "APA功能是否激活";
CM_ SG_ 401 APS_VBU_BrakeFunctionMode "制动功能模式";
CM_ SG_ 401 APS_VBU_Speed_Limitation "APS限速值";
CM_ SG_ 401 APS_VBU_Target_Gear_Request "目标档位";
CM_ SG_ 401 APS_AVM_HU_CurrentSts "APS/AVM上报给HU的当前状态";
CM_ SG_ 401 APS_HU_ParkPrompttone "找到车位提示音";
CM_ SG_ 401 APS_VBU_APAFailed "APA反馈VBU的故障状态";
CM_ SG_ 401 APS_AVM_FactoryMode "APS/AVM工厂模式状态";
CM_ SG_ 401 APS_TBOXConect_ParkInResp "接收TBOX与手机的连接状态，并反馈给TBOX，作为APP端发起请求遥控泊入的前提条件之一";
CM_ SG_ 401 APS_VBU_FailureBrakeMode "刹车模式失效状态";
CM_ SG_ 401 APS_VBU_Stop_Distance "停车距离";
CM_ SG_ 401 APS_R_Gear_RequestTips "换入R档请求";
CM_ SG_ 401 APS_VBU_Req_StraightOut "APS请求遥控直出或者直入的握手请求";
CM_ SG_ 401 APS_VBU_BrakeModeSts "制动模式状态";
CM_ SG_ 401 APS_VBU_Req_StraightCtrol "APS请求遥控直出、直入或者停止命令";
CM_ SG_ 401 RollingCounter_0x191 "RollingCounter: used 4bit length signal and the arithmetic is increased from 0 to 15 by every message.";
CM_ SG_ 404 Checksum_0x194 "Checksum: IDMSB XOR IDLSB XOR Byte1 XOR Byte2 XOR Byte3 XOR Byte4 XOR Byte5 XOR Byte6 XOR Byte7";
CM_ SG_ 404 APS_PA_DistanceValueLR_FL "左前长距离雷达探测障碍物距离值（P2选装包）";
CM_ SG_ 404 APS_PA_DistanceValueLR_FR "右前长距离雷达探测障碍物距离值（P2选装包）";
CM_ SG_ 404 APS_PA_DistanceValueSR_FL "左前短距离雷达探测障碍物距离值（中高配）";
CM_ SG_ 404 APS_PA_DistanceValueSR_FML "左中前短距离雷达探测障碍物距离值（中高配）";
CM_ SG_ 404 APS_PA_DistanceValueSR_FMR "右中前短距离雷达探测障碍物距离值（中高配）";
CM_ SG_ 404 APS_PA_DistanceValueSR_FR "右前短距离雷达探测障碍物距离值（中高配）";
CM_ SG_ 404 RollingCounter_0x194 "RollingCounter: used 4bit length signal and the arithmetic is increased from 0 to 15 by every message.";
CM_ SG_ 405 Checksum_0x195 "Checksum: IDMSB XOR IDLSB XOR Byte1 XOR Byte2 XOR Byte3 XOR Byte4 XOR Byte5 XOR Byte6 XOR Byte7";
CM_ SG_ 405 APS_PA_DistanceValueLR_RL "左后长距离雷达探测障碍物距离值（P2选装包）";
CM_ SG_ 405 APS_PA_DistanceValueLR_RR "右后长距离雷达探测障碍物距离值（P2选装包）";
CM_ SG_ 405 APS_PA_DistanceValueSR_RL "左后短距离雷达探测障碍物距离值（中高配）";
CM_ SG_ 405 APS_PA_DistanceValueSR_RML "左中后短距离雷达探测障碍物距离值（中高配）";
CM_ SG_ 405 APS_PA_DistanceValueSR_RMR "右中后短距离雷达探测障碍物距离值（中高配）";
CM_ SG_ 405 APS_PA_DistanceValueSR_RR "右后短距离雷达探测障碍物距离值（中高配）";
CM_ SG_ 405 RollingCounter_0x195 "RollingCounter: used 4bit length signal and the arithmetic is increased from 0 to 15 by every message.";
CM_ SG_ 406 APS_PA_Buzzer_Alarm_F "蜂鸣器报警方式-前(中高配）";
CM_ SG_ 406 APS_PA_Buzzer_Alarm_R "蜂鸣器报警方式-后(中高配）";
CM_ SG_ 406 APS_PA_DISTANCE_FL "倒车雷达左前区距离显示(中高配）";
CM_ SG_ 406 APS_PA_DISTANCE_FML "倒车雷达左中前区距离显示（中高配）";
CM_ SG_ 406 APS_PA_DISTANCE_FMR "倒车雷达右中前区距离显示（中高配）";
CM_ SG_ 406 APS_PA_DISTANCE_FR "倒车雷达右前区距离显示（中高配）";
CM_ SG_ 406 APS_PAS_DISTANCE_RL "倒车雷达左后区距离显示（中高配）";
CM_ SG_ 406 APS_PA_DISTANCE_RML "倒车雷达左中后区距离显示（高配）";
CM_ SG_ 406 APS_PA_DISTANCE_RMR "倒车雷达右中后区距离显示（中高配）";
CM_ SG_ 406 APS_PAS_DISTANCE_RR "倒车雷达右后区距离显示（中高配）";
CM_ SG_ 406 APS_PA_DISTANCE_LSF "倒车雷达前左侧区距离显示（P2选装包）";
CM_ SG_ 406 APS_PA_DISTANCE_RSF "倒车雷达前右侧区距离显示（P2选装包）";
CM_ SG_ 406 APS_PA_DISTANCE_LSR "倒车雷达后左侧区距离显示（P2选装包）";
CM_ SG_ 406 APS_PA_DISTANCE_RSR "倒车雷达后右侧区距离显示（P2选装包）";
CM_ SG_ 406 APS_PA_WorkSts "PDC Work Status
PDC 工作状态";
CM_ SG_ 406 APS_PA_MODE "倒车雷达的工作模式";
CM_ SG_ 529 Checksum_0x211 "Checksum: IDMSB XOR IDLSB XOR Byte1 XOR Byte2 XOR Byte3 XOR Byte4 XOR Byte5 XOR Byte6 XOR Byte7";
CM_ SG_ 529 ABS_WheelSpeed_FL "Current wheel speed information of front left wheel.
左前轮轮速";
CM_ SG_ 529 ABS_WheelSpeed_FR "Current wheel speed information of front right wheel.
右前轮轮速";
CM_ SG_ 529 ABS_WheelSpeed_RL "Current wheel speed information of rear left wheel.
左后轮轮速";
CM_ SG_ 529 ABS_WheelSpeed_RR "Current wheel speed information of rear right wheel.
右后轮轮速";
CM_ SG_ 529 RollingCounter_0x211 "RollingCounter: used 4bit length signal and the arithmetic is increased from 0 to 15 by every message.";
CM_ SG_ 529 ABS_WheelSpeed_FL_Valid "Front left wheel speed valid
左前轮速有效";
CM_ SG_ 529 ABS_WheelSpeed_FR_Valid "Front right wheel speed valid
右前轮速有效";
CM_ SG_ 529 ABS_WheelSpeed_RL_Valid "Rear left wheel speed valid 
左后轮速有效";
CM_ SG_ 529 ABS_WheelSpeed_RR_Valid "Rear right wheel speed valid
右后轮速有效";
CM_ SG_ 532 Checksum_0x214 "Checksum: IDMSB XOR IDLSB XOR Byte1 XOR Byte2 XOR Byte3 XOR Byte4 XOR Byte5 XOR Byte6 XOR Byte7";
CM_ SG_ 532 ESP_WheelDirection_FL "Front left wheel Moving direction";
CM_ SG_ 532 ESP_WheelDirection_FL_Valid "Indicating front left wheel direction signal valid or not.";
CM_ SG_ 532 ESP_WheelDirection_FR "Front right wheel  Moving direction";
CM_ SG_ 532 ESP_WheelDirection_FR_Valid "Indicating front right wheel direction signal valid or not.";
CM_ SG_ 532 ESP_WheelDirection_RL "Rear left wheel  Moving direction";
CM_ SG_ 532 ESP_WheelDirection_RL_Valid "Indicating rear left wheel direction signal valid or not.";
CM_ SG_ 532 ESP_WheelDirection_RR "Rear right wheel Moving direction";
CM_ SG_ 532 ESP_WheelDirection_RR_Valid "Indicating rear right wheel direction signal valid or not.";
CM_ SG_ 532 ESP_CDD_Intervention "Indicates CDD is active or not";
CM_ SG_ 532 ESP_CDD_Available "Indicates CDD is available or not";
CM_ SG_ 532 ESP_CDD_Error "Indicate whether or not CDD is off and the function degrades due to errors. 
Note: CDD error does not apply to ESP error.";
CM_ SG_ 532 ESP_CDDTempOff "Indicating brake temperature too high or not.";
CM_ SG_ 532 ESP_VLC_EngTrqReq "VLC engine Torque Request
0x4E20-0x7FFF:Invalid signal";
CM_ SG_ 532 ESP_VLC_EngTrqReqActive "VLC engine Torque Request Active";
CM_ SG_ 532 RollingCounter_0x214 "RollingCounter: used 4bit length signal and the arithmetic is increased from 0 to 15 by every message.";
CM_ SG_ 532 ESP_VLC_Intervention "Indicates VLC is active or not
";
CM_ SG_ 532 ESP_VLC_Error "It means VLC is failed";
CM_ SG_ 532 ESP_VLC_Available "It means VLC is available";
CM_ SG_ 533 Checksum_0x215 "Checksum: IDMSB XOR IDLSB XOR Byte1 XOR Byte2 XOR Byte3 XOR Byte4 XOR Byte5 XOR Byte6 XOR Byte7";
CM_ SG_ 533 ABS_WheelPulse_FL_Valid " Previous name: WheelPulse_FL_Valid: Means Indicating front left wheel pulse signal valid or not.";
CM_ SG_ 533 ABS_WheelPulse_FR_Valid " Previous name: WheelPulse_FR_Valid: Means Indicating front left wheel pulse signal valid or not.";
CM_ SG_ 533 ABS_WheelPulse_RL_Valid " Previous name: WheelPulse_RL_Valid: Means Indicating front left wheel pulse signal valid or not.";
CM_ SG_ 533 ABS_WheelPulse_RR_Valid " Previous name: WheelPulse_RR_Valid: Means Indicating front left wheel pulse signal valid or not.";
CM_ SG_ 533 ABS_WheelPulse_FL " Previous name: WheelPulse_FL, means Front left wheel pulse";
CM_ SG_ 533 ABS_WheelPulse_FR " Previous name: WheelPulse_FR, means Front left wheel pulse";
CM_ SG_ 533 ABS_WheelPulse_RL " Previous name: WheelPulse_RL, means Front left wheel pulse";
CM_ SG_ 533 ABS_WheelPulse_RR " Previous name: WheelPulse_RR, means Front left wheel pulse";
CM_ SG_ 533 RollingCounter_0x215 "RollingCounter: used 4bit length signal and the arithmetic is increased from 0 to 15 by every message.";
CM_ SG_ 579 ESP_YawRateValue "yaw rate signal
横摆角速度";
CM_ SG_ 579 ESP_YawrateValue_valid "yaw rate signal value valid or not.横摆角速度信号是否有效";
CM_ SG_ 579 ESP_LongAccSensor "vehicle longitudinal acceleration
车辆纵向加速度";
CM_ SG_ 579 ESP_LongAccSensorValid "vehicle longitudinal acceleration  value valid or not.
车辆纵向加速度信号是否有效";
CM_ SG_ 579 ESP_LaterAccSensor "vehicle lateral acceleration
车辆横向加速度";
CM_ SG_ 579 ESP_LaterAccSensorValid "vehicle lateral acceleration value valid or not.
车辆横向加速度信号是否有效";
CM_ SG_ 579 ESP_AEB_Available "Check whether AEB function is available or not.";
CM_ SG_ 579 ESP_AEB_Intervention "Indicates AEB is active or not";
CM_ SG_ 580 Checksum_0x244 "Checksum: IDMSB XOR IDLSB XOR Byte1 XOR Byte2 XOR Byte3 XOR Byte4 XOR Byte5 XOR Byte6 XOR Byte7";
CM_ SG_ 580 ESP_VLC_InternalTgtAx "Calculated VLC internal target deceleration.";
CM_ SG_ 580 ESP_AWB_Available "Check whether AWB function is available or not.";
CM_ SG_ 580 ESP_AWB_Intervention "AWB active";
CM_ SG_ 580 ESP_ABA_Available "Check whether ABA function is available or not.";
CM_ SG_ 580 ESP_ABA_Intervention "Indicates ABA is active or not";
CM_ SG_ 580 ESP_ABP_Available "Check whether ABP function is available or not.";
CM_ SG_ 580 ESP_ABP_Intervention "Indicates ABP is active or not";
CM_ SG_ 580 ESP_VirtualGaspadelPosReq "ESC_VirtualGaspadelPosReq";
CM_ SG_ 580 ESC_CDPIntervention "Indicates CDP control active";
CM_ SG_ 580 ESC_CDPErrorSt "HMI Responsible,CAN get degrateCDP statement from DSW and send out";
CM_ SG_ 580 RollingCounter_0x244 "RollingCounter: used 4bit length signal and the arithmetic is increased from 0 to 15 by every message.";
CM_ SG_ 624 Checksum_0x270 "Checksum: IDMSB XOR IDLSB XOR Byte1 XOR Byte2 XOR Byte3 XOR Byte4 XOR Byte5 XOR Byte6 XOR Byte7";
CM_ SG_ 624 APS_TrgtEPSStrgWhlAng "Advanced Park Assist Target Electric Power Steering Steering Wheel Angle
APA需求的目标转向角度";
CM_ SG_ 624 APS_APAFailed "Advanced Park Assist Failed 
APA故障";
CM_ SG_ 624 APS_CmdEPSSts "Advanced Park Assist Command Electric Power Steering Status
APA状态";
CM_ SG_ 624 RollingCounter_0x270 "RollingCounter: used 4bit length signal and the arithmetic is increased from 0 to 15 by every message.";
CM_ SG_ 625 Checksum_0x271 "Checksum: IDMSB XOR IDLSB XOR Byte1 XOR Byte2 XOR Byte3 XOR Byte4 XOR Byte5 XOR Byte6 XOR Byte7";
CM_ SG_ 625 APS_AutoSearchSts "自动泊车车位搜寻状态";
CM_ SG_ 625 APS_ParkOutChkResult "当前是否满足泊出条件";
CM_ SG_ 625 APS_CurrentPathNum "本次泊车中的当前所处路径数";
CM_ SG_ 625 APS_TotalPathNum "本次泊车需要的总路径数";
CM_ SG_ 625 APS_SuspendedReason "主动泊车暂停原因";
CM_ SG_ 625 APS_AbortReason "主动泊车中止原因";
CM_ SG_ 625 APS_CurrentParkType "当前选择的泊车类型";
CM_ SG_ 625 APS_OverrideReason "主动泊车驾驶员介入原因";
CM_ SG_ 625 APS_VehicleDirection "在当前路径中车辆行驶方向";
CM_ SG_ 625 APS_TerminatedType "APA终止类型";
CM_ SG_ 625 APS_ParkOutSystemStatus "APA泊出系统状态";
CM_ SG_ 625 APS_CurrentStepNum "在当前路径中所处的步数";
CM_ SG_ 625 APS_RemoteParkIn_Status "遥控泊入状态";
CM_ SG_ 625 APS_RemoteParkInResp "响应APP的遥控泊入请求";
CM_ SG_ 625 APS_BCM_RemoteParkIn_Status "APS请求BCM控制状态位";
CM_ SG_ 625 APS_BCM_DoubleFlash "APS请求BCM双闪";
CM_ SG_ 625 APS_BCM_AllDoorUnLock_Door "APS请求BCM解锁";
CM_ SG_ 625 APS_RemoteParkOutResp "响应APP的遥控泊出请求";
CM_ SG_ 625 APS_BCM_PowerOffReq "遥控泊车完成后下电请求发送给BCM";
CM_ SG_ 625 APS_RemotePark_Error_Status "遥控泊车故障";
CM_ SG_ 625 RollingCounter_0x271 "RollingCounter: used 4bit length signal and the arithmetic is increased from 0 to 15 by every message.";
CM_ SG_ 642 SCM_PRND_req "PRND档位请求";
CM_ SG_ 674 HU_APS_Audio_Active "语音激活泊车开启";
CM_ SG_ 674 HU_Audio_AP_Request "HU_Audio_AP_Request
语音泊车控制请求";
CM_ SG_ 674 HU_Audio_Request_Command "语音控制请求";
CM_ SG_ 674 HU_AVM_ViewModeSwitch "Hu给AVM/APS发送视图切换请求";
CM_ SG_ 674 HU_Display_Mode_APA "白天夜晚模式";
CM_ SG_ 784 BCM_SystemPowerMode "整车电源状态
vehicle Power Status";
CM_ SG_ 784 BCM_DriverLock_Sts "驾驶侧门锁状态";
CM_ SG_ 784 BCM_PositionLight_Sts "位置灯状态";
CM_ SG_ 784 BCM_TurnLeftLight_Sts "左转向灯状态";
CM_ SG_ 784 BCM_TurnRightLight_Sts "右转向灯状态";
CM_ SG_ 784 BCM_HighBeam_Sts "远光灯状态";
CM_ SG_ 784 BCM_LowBeam_Sts "近光灯状态";
CM_ SG_ 784 BCM_HazardLight_Sts "危险报警指示灯状态";
CM_ SG_ 784 BCM_FL_Door_Sts "左前门状态";
CM_ SG_ 784 BCM_FR_Door_Sts "右前门状态";
CM_ SG_ 784 BCM_RL_Door_Sts "左后门状态";
CM_ SG_ 784 BCM_RR_Door_Sts "右后门状态";
CM_ SG_ 784 BCM_Trunk_Door_Sts "后背门状态（低配）
通过诊断读取2001的配置字，如果PLG不存在则使用此信号
";
CM_ SG_ 784 BCM_RearViewFoldSts "
外后视镜折叠状态（控制状态非实际状态）
信号为折叠状态下：如果手动展开 信号为折叠
信号为展开状态下：如果手动折叠，信号为展开
";
CM_ SG_ 853 TBOX_TimeSyncData_Year "TBOX发送的同步时间数据----年
0x0-0x63: Year
0x64-0x7F: Invalid
";
CM_ SG_ 853 TBOX_TimeSyncData_Month "TBOX发送的同步时间数据----月
0x0: Invalid
0x1-0xC: Month";
CM_ SG_ 853 TBOX_TimeSyncData_Day "TBOX发送的同步时间数据----日
0x0: Invalid
0x01-0x1F: Day";
CM_ SG_ 853 TBOX_TimeSyncData_Hour "ACM发送的同步时间数据----时
0x0-0x17: Hour
0x18-0x1F: Invalid";
CM_ SG_ 853 TBOX_TimeSyncData_Minute "TBOX发送的同步时间数据----分
0x0-0x3B: Minute
0x3C-0x3F: Invalid
";
CM_ SG_ 853 TBOX_TimeSyncData_Second "TBOX发送的同步时间数据----秒
0x00-0x3B: Second
0x3C-0x3F: Invalid
";
CM_ SG_ 928 ICM_DisPlayVehicleSpeed "Current Display Vehicle Speed
仪表当前显示车速";
CM_ SG_ 1484 SWVersion_Supplier "APS转发的PA软件供应商代码（有天际定义，如A/B/C分别代表A点/B点/C点供应商，定义参考诊断规范版本号定义）";
CM_ SG_ 1484 SWVersion_Main "APS转发的PA软件版本-大版本";
CM_ SG_ 1484 SWVersion_Sub1 "APS转发的PA软件版本-小版本第一位";
CM_ SG_ 1484 SWVersion_Sub2 "APS转发的PA软件版本-小版本第二位";
CM_ SG_ 1484 HWVersion_Supplier "APS转发的PA硬件件供应商代码";
CM_ SG_ 1484 HWVersion_Main "APS转发的PA硬件版本-大版本";
CM_ SG_ 1484 HWVersion_Sub1 "APS转发的PA硬件版本-小版本第一位";
CM_ SG_ 1484 HWVersion_Sub2 "APS转发的PA硬件版本-小版本第二位";
CM_ SG_ 1516 APS_SWVersion_Supplier "APS软件供应商代码（有天际定义，如A/B/C分别代表A点/B点/C点供应商，定义参考诊断规范版本号定义）";
CM_ SG_ 1516 APS_SWVersion_Main "APS软件版本-大版本";
CM_ SG_ 1516 APS_SWVersion_Sub1 "APS软件版本-小版本第一位";
CM_ SG_ 1516 APS_SWVersion_Sub2 "APS软件版本-小版本第二位";
CM_ SG_ 1516 APS_HWVersion_Supplier "APS硬件件供应商代码";
CM_ SG_ 1516 APS_HWVersion_Main "APS硬件版本-大版本";
CM_ SG_ 1516 APS_HWVersion_Sub1 "APS硬件版本-小版本第一位";
CM_ SG_ 1516 APS_HWVersion_Sub2 "APS硬件版本-小版本第二位";
CM_ SG_ 1829 APS_UDSDiag_ReqPhsy_0x725 "APS UDS诊断物理寻址ID，数据位根据需求供应商可自定义";
CM_ SG_ 1837 APS_UDSDiag_Resp_0x72D "APS UDS诊断响应ID，数据位根据需求供应商可自定义";
CM_ SG_ 2015 UDSDiag_ReqFunc_0x7DF "整车UDS诊断功能寻址ID，数据位根据需求供应商可自定义";
CM_ SG_ 1841 PA_UDSDiag_ReqPhsy_0x731 "PA UDS诊断物理寻址ID，数据位根据需求供应商可自定义";
CM_ SG_ 1849 PA_UDSDiag_Resp_0x739 "PA UDS诊断响应ID，数据位根据需求供应商可自定义";
BA_DEF_ BO_  "DiagState" ENUM  "No","Yes";
BA_DEF_ BO_  "DiagRequest" ENUM  "No","Yes";
BA_DEF_ BO_  "DiagResponse" ENUM  "No","Yes";
BA_DEF_ BO_  "GenMsgSendType" ENUM  "Cyclic","IfActive","Event","CA","CE","NoMsgSendType";
BA_DEF_ BO_  "GenMsgCycleTime" INT 0 0;
BA_DEF_ SG_  "GenSigSendType" ENUM  "Cyclic","OnChange","OnWrite","IfActive","OnChangeWithRepetition","OnWriteWithRepetition","IfActiveWithRepetition","NoSigSendType","OnChangeAndIfActive","OnChangeAndIfActiveWithRepetition","CA","CE","Event";
BA_DEF_ SG_  "GenSigStartValue" INT 0 0;
BA_DEF_  "DBName" STRING ;
BA_DEF_ BU_  "NodeLayerModules" STRING ;
BA_DEF_ BU_  "NmNode" ENUM  "Not","Yes";
BA_DEF_  "NmBaseAddress" HEX 0 2047;
BA_DEF_  "NmMessageCount" INT 0 255;
BA_DEF_ BO_  "GenMsgILSupport" ENUM  "No","Yes";
BA_DEF_  "BusType" STRING ;
BA_DEF_DEF_  "DiagState" "No";
BA_DEF_DEF_  "DiagRequest" "No";
BA_DEF_DEF_  "DiagResponse" "No";
BA_DEF_DEF_  "GenMsgSendType" "Cyclic";
BA_DEF_DEF_  "GenMsgCycleTime" 0;
BA_DEF_DEF_  "GenSigSendType" "Cyclic";
BA_DEF_DEF_  "GenSigStartValue" 0;
BA_DEF_DEF_  "DBName" "";
BA_DEF_DEF_  "NodeLayerModules" "CANoeILNLVector.dll";
BA_DEF_DEF_  "NmNode" "Not";
BA_DEF_DEF_  "NmBaseAddress" 1024;
BA_DEF_DEF_  "NmMessageCount" 128;
BA_DEF_DEF_  "GenMsgILSupport" "No";
BA_DEF_DEF_  "BusType" "CAN";
BA_ "DBName" "ME5_ADASCAN";
BA_ "GenMsgCycleTime" BO_ 402 50;
BA_ "GenMsgILSupport" BO_ 402 1;
BA_ "GenMsgCycleTime" BO_ 403 50;
BA_ "GenMsgILSupport" BO_ 403 1;
BA_ "GenMsgCycleTime" BO_ 851 100;
BA_ "GenMsgILSupport" BO_ 851 1;
BA_ "GenMsgCycleTime" BO_ 289 20;
BA_ "GenMsgILSupport" BO_ 289 1;
BA_ "GenMsgCycleTime" BO_ 305 20;
BA_ "GenMsgILSupport" BO_ 305 1;
BA_ "GenMsgCycleTime" BO_ 321 20;
BA_ "GenMsgILSupport" BO_ 321 1;
BA_ "GenMsgCycleTime" BO_ 337 20;
BA_ "GenMsgILSupport" BO_ 337 1;
BA_ "GenMsgCycleTime" BO_ 341 100;
BA_ "GenMsgILSupport" BO_ 341 1;
BA_ "GenMsgCycleTime" BO_ 352 20;
BA_ "GenMsgILSupport" BO_ 352 1;
BA_ "GenMsgCycleTime" BO_ 373 10;
BA_ "GenMsgILSupport" BO_ 373 1;
BA_ "GenMsgCycleTime" BO_ 375 10;
BA_ "GenMsgILSupport" BO_ 375 1;
BA_ "GenMsgILSupport" BO_ 401 1;
BA_ "GenMsgCycleTime" BO_ 401 10;
BA_ "GenMsgILSupport" BO_ 404 1;
BA_ "GenMsgCycleTime" BO_ 404 100;
BA_ "GenMsgILSupport" BO_ 405 1;
BA_ "GenMsgCycleTime" BO_ 405 100;
BA_ "GenMsgILSupport" BO_ 406 1;
BA_ "GenMsgCycleTime" BO_ 406 100;
BA_ "GenMsgCycleTime" BO_ 529 20;
BA_ "GenMsgILSupport" BO_ 529 1;
BA_ "GenMsgCycleTime" BO_ 532 20;
BA_ "GenMsgILSupport" BO_ 532 1;
BA_ "GenMsgCycleTime" BO_ 533 20;
BA_ "GenMsgILSupport" BO_ 533 1;
BA_ "GenMsgCycleTime" BO_ 579 20;
BA_ "GenMsgILSupport" BO_ 579 1;
BA_ "GenMsgCycleTime" BO_ 580 20;
BA_ "GenMsgILSupport" BO_ 580 1;
BA_ "GenMsgILSupport" BO_ 624 1;
BA_ "GenMsgCycleTime" BO_ 624 20;
BA_ "GenMsgILSupport" BO_ 625 1;
BA_ "GenMsgCycleTime" BO_ 625 50;
BA_ "GenMsgCycleTime" BO_ 642 20;
BA_ "GenMsgILSupport" BO_ 642 1;
BA_ "GenMsgCycleTime" BO_ 674 100;
BA_ "GenMsgILSupport" BO_ 674 1;
BA_ "GenMsgILSupport" BO_ 678 1;
BA_ "GenMsgCycleTime" BO_ 678 10;
BA_ "GenMsgCycleTime" BO_ 784 50;
BA_ "GenMsgILSupport" BO_ 784 1;
BA_ "GenMsgCycleTime" BO_ 853 1000;
BA_ "GenMsgILSupport" BO_ 853 1;
BA_ "GenMsgCycleTime" BO_ 928 100;
BA_ "GenMsgILSupport" BO_ 928 1;
BA_ "GenMsgILSupport" BO_ 1484 1;
BA_ "GenMsgCycleTime" BO_ 1484 10000;
BA_ "GenMsgILSupport" BO_ 1516 1;
BA_ "GenMsgCycleTime" BO_ 1516 10000;
BA_ "GenMsgSendType" BO_ 1829 2;
BA_ "DiagRequest" BO_ 1829 1;
BA_ "GenMsgSendType" BO_ 1837 2;
BA_ "DiagResponse" BO_ 1837 1;
BA_ "GenMsgSendType" BO_ 2015 2;
BA_ "DiagState" BO_ 2015 1;
BA_ "GenMsgSendType" BO_ 1841 2;
BA_ "GenMsgSendType" BO_ 1849 2;
BA_ "GenSigSendType" SG_ 851 TBOX_APS_EPSStrgWhlAngZero 1;
BA_ "GenSigSendType" SG_ 851 TBOX_APS_PoewerOff_Request 1;
BA_ "GenSigSendType" SG_ 851 TBOX_APS_PowerON_Request 1;
BA_ "GenSigStartValue" SG_ 532 ESP_VLC_EngTrqReq 10000;
BA_ "GenSigSendType" SG_ 642 SCM_PRND_req 1;
BA_ "GenSigSendType" SG_ 674 HU_Audio_AP_Request 1;
BA_ "GenSigSendType" SG_ 674 HU_Audio_Request_Command 1;
BA_ "GenSigSendType" SG_ 674 HU_AVM_ViewModeSwitch 1;
BA_ "GenSigStartValue" SG_ 853 TBOX_TimeSyncData_Month 1;
BA_ "GenSigStartValue" SG_ 853 TBOX_TimeSyncData_Day 1;
BA_ "GenSigSendType" SG_ 1829 APS_UDSDiag_ReqPhsy_0x725 1;
BA_ "GenSigSendType" SG_ 1837 APS_UDSDiag_Resp_0x72D 1;
BA_ "GenSigSendType" SG_ 2015 UDSDiag_ReqFunc_0x7DF 1;
BA_ "GenSigSendType" SG_ 1841 PA_UDSDiag_ReqPhsy_0x731 1;
BA_ "GenSigSendType" SG_ 1849 PA_UDSDiag_Resp_0x739 1;
VAL_ 402 SDAR_EnableSts 1 "enable" 0 "disable" ;
VAL_ 402 SDAR_Sysfault 1 "Error" 0 "No error" ;
VAL_ 402 SDAR_BSD_LCA_EnableSts 1 "enable" 0 "disable" ;
VAL_ 402 SDAR_RCTA_EnableSts 1 "enable" 0 "disable" ;
VAL_ 402 SDAR_DOW_EnableSts 1 "enable" 0 "disable" ;
VAL_ 402 SDAR_WarnLevel 3 "Reserved" 2 "Warning level 2" 1 "Warning level 1" 0 "Inactive" ;
VAL_ 402 SDAR_WorkSts 3 "DOW mode" 2 "RCTA mode" 1 "BSD mode" 0 "NOwarning" ;
VAL_ 403 SDAL_EnableSts 1 "enable" 0 "disable" ;
VAL_ 403 SDAL_Sysfault 1 "Error" 0 "No error" ;
VAL_ 403 SDAL_BSD_LCA_EnableSts 1 "enable" 0 "disable" ;
VAL_ 403 SDAL_RCTA_EnableSts 1 "enable" 0 "disable" ;
VAL_ 403 SDAL_DOW_EnableSts 1 "enable" 0 "disable" ;
VAL_ 403 SDAL_WarnLevel 3 "Reserved" 2 "Warning level 2" 1 "Warning level 1" 0 "Inactive" ;
VAL_ 403 SDAL_WorkSts 3 "DOW mode" 2 "RCTA mode" 1 "BSD mode" 0 "NOwarning" ;
VAL_ 851 TBOX_BTKey_valid 1 "蓝牙已连接可用" 0 "蓝牙未连接不可用" ;
VAL_ 851 TBOX_APS_EPSStrgWhlAngZero 1 "回正" 0 "default" ;
VAL_ 851 TBOX_APS_RequstRemoteParkOut 1 "Request" 0 "NoRequest" ;
VAL_ 851 TBOX_APS_StartRemoteParkOut 1 "press" 0 "nopress" ;
VAL_ 851 TBOX_APS_RequstRemoteParkIn 1 "Request" 0 "NoRequest" ;
VAL_ 851 TBOX_APS_StartRemoteParkIn 1 "press" 0 "nopress" ;
VAL_ 851 TBOX_APS_PoewerOff_Request 3 "Resvered" 2 "PowerOffReqiest" 1 "NoPowerOffReqiest" 0 "Default" ;
VAL_ 851 TBOX_APS_StraightOut_Request1 3 "Undo 松开停止转向" 2 "Right 右转" 1 "Left 左转" 0 "Default" ;
VAL_ 851 TBOX_APS_StraightOut_Request2 3 "STOP松开停止驱动" 2 "后退" 1 "前进" 0 "Default" ;
VAL_ 851 TBOX_APS_PowerON_Request 3 "strat request" 2 "reserved" 1 "resverd" 0 "Default" ;
VAL_ 289 ESP_VehicleSpeed_Valid 1 "Invalid" 0 "Valid" ;
VAL_ 289 ESP_ABS_Error 1 "Failure" 0 "No failure" ;
VAL_ 289 ESP_ABS_Intervention 1 "Active" 0 "Not active" ;
VAL_ 289 ESP_VDC_TCS_Error 1 "On" 0 "Off" ;
VAL_ 289 ESP_EBD_Error 1 "On" 0 "Off" ;
VAL_ 289 ESP_VDC_Intervention 1 "Active" 0 "Not active" ;
VAL_ 289 ESP_TCS_Intervention 1 "Active" 0 "Not active" ;
VAL_ 289 ESP_EBD_Intervention 1 "Active" 0 "Not active" ;
VAL_ 289 ESP_HDC_Available 1 "Available" 0 "Not available" ;
VAL_ 289 ESP_EPBMainteDiagmodeActive 1 "Active" 0 "Not active" ;
VAL_ 289 ESP_EPBStatus 7 ":Reserved" 6 ":Reserved" 5 ":Reserved" 4 "Locking（卡钳正处于夹紧过程中" 3 "Releasing（卡钳正处于释放过程中）" 2 "Closed（卡钳处于夹紧状态）" 1 "Released（卡钳处于释放状态）" 0 "Undefined（未定义）" ;
VAL_ 289 ESP_VehicleStop 1 "2 or more wheels are standstill" 0 "Vehicle is not standstill" ;
VAL_ 289 ESP_VehicleStop_Valid 1 "Valid" 0 "Invalid" ;
VAL_ 289 ESP_WheelCyBrakeForce_Exist 1 "brake force exists" 0 "No brake force" ;
VAL_ 289 ESP_HHC_Available 1 "Available" 0 "Not available" ;
VAL_ 289 ESP_HHCActive 1 "Active" 0 "Not active" ;
VAL_ 305 MRR_ACC_Status 15 ":Reserved" 14 ":Reserved" 13 ":Reserved" 12 ":Reserved" 11 ":Reserved" 10 ":Reserved" 9 ":Reserved" 8 "Service required" 7 "System temporary unavailable；" 6 "Standstill wait ；" 5 "Standstill active；" 4 "Override；" 3 "Brake-Only ；" 2 "Active；" 1 "Stand-By ；" 0 "OFF ；" ;
VAL_ 321 VBU_APS_LC_Availability 3 "保留" 2 "LongCtrl_AutomaticPark" 1 "LongCtrl_ParkEmergencyBrake" 0 "No_LongCtrl_Support" ;
VAL_ 321 VBU_APS_LC_FailureSts 7 "ParkAssist_WithError" 6 "ParkAssist_Reserved" 5 "ParkAssist_Unexpected_GearIntervention" 4 "ParkAssist_Unexpected_Brake" 3 "ParkAssist_Unexpected_EPB_Action" 2 "ParkAssist_Unexpected_GearPosition" 1 "ParkAssist_Vehicle_block" 0 "ParkAssist_NoError" ;
VAL_ 321 VBU_APS_LC_Status 10 "LongCtrl_Error" 9 "LongCtrl_Active_ManeuverAccelerationAvoidance" 8 "LongCtrl_Active_ManeuverComfortBrake" 7 "LongCtrl_Active_ManeuverEmergencyBrake" 6 "LongCtrl_Active_RemoteParkOut" 5 "LongCtrl_Active_RemoteParkIn" 4 "LongCtrl_Active_AutomaticPark" 3 "LongCtrl_Active_ParkEmergencyBrake" 2 "LongCtrl_Active_ParkComfortBrake" 1 "LongCtrl_Standby" 0 "LongCtrl_Off" ;
VAL_ 337 VBU_BrkPed_Pos 255 "Invalid" ;
VAL_ 337 VBU_AccPedPos 255 "Invalid" ;
VAL_ 337 VBU_TargetGear 7 "Invalid" 6 "Reserved" 5 "Reserved" 4 "Reserved" 3 "D" 2 "N" 1 "R" 0 "P" ;
VAL_ 337 VBU_APS_WorkStatus 22 "预留故障1" 21 "APS通讯故障" 20 "动力系统故障" 19 "人为介入停止" 18 "EPB释放超时" 17 "EPB故障" 16 "FMCU反馈转速模式超时" 15 "分配给电机的功率不满足" 14 "车速不满足" 13 "FMCU工作状态不满足" 12 "整车电源档位不满足" 11 "不在P档" 10 "VBU检测坡度不满足" 7 "正在脱手（由APS发起）" 6 "已激活状态:暂停" 5 "已激活状态:后退" 4 "已激活状态:前进" 3 "已激活状态:停止" 2 "正在握手" 1 "Standby待机状态" 0 "Init" ;
VAL_ 341 SWS_L_360keyStatus 3 "Reserved" 2 "Reserved" 1 "Press" 0 "No press" ;
VAL_ 352 GW_VBU_GearLeverPos 7 "Invalid" 6 "Reserved" 5 "Reserved" 4 "Reserved" 3 "D" 2 "N" 1 "R" 0 "P" ;
VAL_ 352 GW_VBU_ReadySts 1 "Ready" 0 "Not Ready" ;
VAL_ 352 GW_VBU_BrkSw_Sts 3 "Error" 2 "Reserved" 1 "Pressed" 0 "NotPressed" ;
VAL_ 352 CSW_Key_APA_GW 3 "Reserved" 2 "Reserved" 1 "pressed" 0 "not pressed" ;
VAL_ 352 PLG_Latc_PawlSW 1 "active尾门打开" 0 "inactive尾门关闭" ;
VAL_ 352 BCM_FrontdecoralampSW 1 "on" 0 "off" ;
VAL_ 373 SAS_SteerWheelRotSpd 16383 "Invalid signal" ;
VAL_ 373 SAS_SteerWheelRotSpdStatus 1 "Invalid" 0 "Valid" ;
VAL_ 373 SAS_SASStsSnsr 1 "sensor value  valid" 0 "sensor value  Invalid" ;
VAL_ 373 EPS_SteeringTorqueValid 1 "Invalid" 0 "Vaild" ;
VAL_ 373 SAS_SASStsCal 1 "sensor calibrated" 0 "sensor not calibrated" ;
VAL_ 375 EPS_EPSAPASts 7 "Failure" 6 "ADAS active" 5 "NRCD active" 4 "Reply for Control" 3 "Abort" 2 "Active" 1 "Available" 0 "Inhibit" ;
VAL_ 375 EPS_EPSAPAInh 16 "EPS failure" 8 "Excess Angle Deviation" 4 "Abnormal CAN input" 2 "Driver Interference" 1 "Over Speed" 0 "Normal Operation" ;
VAL_ 401 APS_SystemSts 7 "Suspend" 6 "Terminated" 5 "Failure" 4 "Completed" 3 "Guidance active" 2 "Searching" 1 "Standby" 0 "Off" ;
VAL_ 401 APS_Active 1 "Active" 0 "Not active" ;
VAL_ 401 APS_VBU_BrakeFunctionMode 15 "reserved" 14 "reserved" 13 "reserved" 12 "reserved" 11 "reserved" 10 "reserved" 9 "reserved" 8 "ParkAssist_ManeuverAccelerationAvoidance" 7 "ParkAssist_ManeuverComfortBrake" 6 "ParkAssist_ManeuverEmergencyBrake" 5 "预留" 4 "预留" 3 "ParkAssist_AutomaticPark" 2 "ParkAssist_ParkEmergencyBrake" 1 "ParkAssist_ParkComfortBrake" 0 "ParkAssist_NoSignal" ;
VAL_ 401 APS_VBU_Speed_Limitation 63 "Invalid" ;
VAL_ 401 APS_VBU_Target_Gear_Request 7 "Reserved" 6 "Reserved" 5 "Reserved" 4 "APADrvDirRqVBU_DRIVE" 3 "APADrvDirRqVBU_NEUTRAL" 2 "APADrvDirRqVBU_Reverse" 1 "APADrvDirRqVBU_Park" 0 "APADrvDirRqVBU_Idle" ;
VAL_ 401 APS_AVM_HU_CurrentSts 7 "Reserved" 6 "APS Request Exit" 5 "VideoStream Output Error" 4 "View Mode-HalfScreen" 3 "View Mode-SoftKey" 2 "View Mode-APA" 1 "View Mode-R" 0 "Not Ready" ;
VAL_ 401 APS_HU_ParkPrompttone 1 "Active" 0 "Not active" ;
VAL_ 401 APS_VBU_APAFailed 1 "APA Failure" 0 "Normal" ;
VAL_ 401 APS_AVM_FactoryMode 1 "Factory_Mode" 0 "Normal_Mode" ;
VAL_ 401 APS_TBOXConect_ParkInResp 3 "Reserved" 2 "蓝牙已连接反馈" 1 "蓝牙未连接反馈" 0 "Default" ;
VAL_ 401 APS_VBU_FailureBrakeMode 3 "ParkAssist_ Emergency" 2 "ParkAssist_Comfort" 1 "ParkAssist_Idle" 0 "ParkAssist_NoFailure" ;
VAL_ 401 APS_R_Gear_RequestTips 3 "Reserved" 2 "RequestTips" 1 "NoRequestTips" 0 "Default" ;
VAL_ 401 APS_VBU_Req_StraightOut 0 "NoRequest                                            0x1: RequestStraightOut" ;
VAL_ 401 APS_VBU_BrakeModeSts 7 "reserved" 6 "reserved" 5 "ParkAssist_Abort" 4 "ParkAssist_Suspend" 3 "ParkAssist_ManeuverFinished" 2 "ParkAssist_Active" 1 "ParkAssist_Standby" 0 "ParkAssist_Int" ;
VAL_ 401 APS_VBU_Req_StraightCtrol 3 "Reserved" 2 "后退" 1 "前进" 0 "停止" ;
VAL_ 404 APS_PA_DistanceValueLR_FL 255 "Invalid" 254 "no object was detected" 253 "Reserved" 252 "Reserved" 251 "Reserved" ;
VAL_ 404 APS_PA_DistanceValueLR_FR 255 "Invalid" 254 "no object was detected" 253 "Reserved" 252 "Reserved" 251 "Reserved" ;
VAL_ 404 APS_PA_DistanceValueSR_FL 127 "Invalid" 126 "no object was detected" ;
VAL_ 404 APS_PA_DistanceValueSR_FML 127 "Invalid" 126 "no object was detected" ;
VAL_ 404 APS_PA_DistanceValueSR_FMR 127 "Invalid" 126 "no object was detected" ;
VAL_ 404 APS_PA_DistanceValueSR_FR 127 "Invalid" 126 "no object was detected" ;
VAL_ 405 APS_PA_DistanceValueLR_RL 255 "Invalid" 254 "no object was detected" 253 "Reserved" 252 "Reserved" 251 "Reserved" ;
VAL_ 405 APS_PA_DistanceValueLR_RR 255 "Invalid" 254 "no object was detected" 253 "Reserved" 252 "Reserved" 251 "Reserved" ;
VAL_ 405 APS_PA_DistanceValueSR_RL 127 "Invalid" 126 "no object was detected" ;
VAL_ 405 APS_PA_DistanceValueSR_RML 127 "Invalid" 126 "no object was detected" ;
VAL_ 405 APS_PA_DistanceValueSR_RMR 127 "Invalid" 126 "no object was detected" ;
VAL_ 405 APS_PA_DistanceValueSR_RR 127 "Invalid" 126 "no object was detected" ;
VAL_ 406 APS_PA_Buzzer_Alarm_F 7 "Reserved" 6 "Reserved" 5 "Reserved" 4 "Front+S4" 3 "Front+S3" 2 "Front+S2" 1 "Front+S1" 0 "Buzzer OFF" ;
VAL_ 406 APS_PA_Buzzer_Alarm_R 7 "Reserved" 6 "Rear+S6" 5 "Rear+S5" 4 "Rear+S4" 3 "Rear+S3" 2 "Rear+S2" 1 "Rear+S1" 0 "Buzzer OFF" ;
VAL_ 406 APS_PA_DISTANCE_FL 7 "Range 7" 6 "Range 6" 5 "Range 5" 4 "Range 4" 3 "Range 3" 2 "Range 2" 1 "Range 1" 0 "No Distance" ;
VAL_ 406 APS_PA_DISTANCE_FML 7 "Range 7" 6 "Range 6" 5 "Range 5" 4 "Range 4" 3 "Range 3" 2 "Range 2" 1 "Range 1" 0 "No Distance" ;
VAL_ 406 APS_PA_DISTANCE_FMR 7 "Range 7" 6 "Range 6" 5 "Range 5" 4 "Range 4" 3 "Range 3" 2 "Range 2" 1 "Range 1" 0 "No Distance" ;
VAL_ 406 APS_PA_DISTANCE_FR 7 "Range 7" 6 "Range 6" 5 "Range 5" 4 "Range 4" 3 "Range 3" 2 "Range 2" 1 "Range 1" 0 "No Distance" ;
VAL_ 406 APS_PAS_DISTANCE_RL 7 "Range 7" 6 "Range 6" 5 "Range 5" 4 "Range 4" 3 "Range 3" 2 "Range 2" 1 "Range 1" 0 "No Distance" ;
VAL_ 406 APS_PA_DISTANCE_RML 7 "Range 7" 6 "Range 6" 5 "Range 5" 4 "Range 4" 3 "Range 3" 2 "Range 2" 1 "Range 1" 0 "No Distance" ;
VAL_ 406 APS_PA_DISTANCE_RMR 7 "Range 7" 6 "Range 6" 5 "Range 5" 4 "Range 4" 3 "Range 3" 2 "Range 2" 1 "Range 1" 0 "No Distance" ;
VAL_ 406 APS_PAS_DISTANCE_RR 7 "Range 7" 6 "Range 6" 5 "Range 5" 4 "Range 4" 3 "Range 3" 2 "Range 2" 1 "Range 1" 0 "No Distance" ;
VAL_ 406 APS_PA_DISTANCE_LSF 7 "Range 7" 6 "Range 6" 5 "Range 5" 4 "Range 4" 3 "Range 3" 2 "Range 2" 1 "Range 1" 0 "No Distance" ;
VAL_ 406 APS_PA_DISTANCE_RSF 7 "Range 7" 6 "Range 6" 5 "Range 5" 4 "Range 4" 3 "Range 3" 2 "Range 2" 1 "Range 1" 0 "No Distance" ;
VAL_ 406 APS_PA_DISTANCE_LSR 7 "Range 7" 6 "Range 6" 5 "Range 5" 4 "Range 4" 3 "Range 3" 2 "Range 2" 1 "Range 1" 0 "No Distance" ;
VAL_ 406 APS_PA_DISTANCE_RSR 7 "Range 7" 6 "Range 6" 5 "Range 5" 4 "Range 4" 3 "Range 3" 2 "Range 2" 1 "Range 1" 0 "No Distance" ;
VAL_ 406 APS_PA_WorkSts 1 "PDC On" 0 "PDC Off" ;
VAL_ 406 APS_PA_MODE 7 "Invalid(Reserved)" 6 "Inhibited" 5 "System Failure" 4 "Rear Active" 3 "Front Active" 2 "Front Rear Active" 1 "Standby" 0 "Off" ;
VAL_ 529 ABS_WheelSpeed_FL 4095 "Invalid" ;
VAL_ 529 ABS_WheelSpeed_FR 4095 "Invalid" ;
VAL_ 529 ABS_WheelSpeed_RL 4095 "Invalid" ;
VAL_ 529 ABS_WheelSpeed_RR 4095 "Invalid" ;
VAL_ 529 ABS_WheelSpeed_FL_Valid 1 "Invalid" 0 "Valid" ;
VAL_ 529 ABS_WheelSpeed_FR_Valid 1 "Invalid" 0 "Valid" ;
VAL_ 529 ABS_WheelSpeed_RL_Valid 1 "Invalid" 0 "Valid" ;
VAL_ 529 ABS_WheelSpeed_RR_Valid 1 "Invalid" 0 "Valid" ;
VAL_ 532 ESP_WheelDirection_FL 3 "Backward" 2 "Forward" 1 "Standstill" 0 "Undefined" ;
VAL_ 532 ESP_WheelDirection_FL_Valid 1 "Valid" 0 "Invalid" ;
VAL_ 532 ESP_WheelDirection_FR 3 "Backward" 2 "Forward" 1 "Standstill" 0 "Undefined" ;
VAL_ 532 ESP_WheelDirection_FR_Valid 1 "Valid" 0 "Invalid" ;
VAL_ 532 ESP_WheelDirection_RL 3 "Backward" 2 "Forward" 1 "Standstill" 0 "Undefined" ;
VAL_ 532 ESP_WheelDirection_RL_Valid 1 "Valid" 0 "Invalid" ;
VAL_ 532 ESP_WheelDirection_RR 3 "Backward" 2 "Forward" 1 "Standstill" 0 "Undefined" ;
VAL_ 532 ESP_WheelDirection_RR_Valid 1 "Valid" 0 "Invalid" ;
VAL_ 532 ESP_CDD_Intervention 1 "Active" 0 "Not active" ;
VAL_ 532 ESP_CDD_Available 1 "Available" 0 "Not available" ;
VAL_ 532 ESP_CDD_Error 1 "Error" 0 "No error" ;
VAL_ 532 ESP_CDDTempOff 1 "temp too high" 0 "not high" ;
VAL_ 532 ESP_VLC_EngTrqReq 32767 "Invalid" ;
VAL_ 532 ESP_VLC_EngTrqReqActive 1 "Active" 0 "Inactive" ;
VAL_ 532 ESP_VLC_Intervention 1 "Active" 0 "Not active" ;
VAL_ 532 ESP_VLC_Error 1 "Failure" 0 "No failure" ;
VAL_ 532 ESP_VLC_Available 1 "Available" 0 "Not available" ;
VAL_ 533 ABS_WheelPulse_FL_Valid 1 "valid" 0 "not valid" ;
VAL_ 533 ABS_WheelPulse_FR_Valid 1 "valid" 0 "not valid" ;
VAL_ 533 ABS_WheelPulse_RL_Valid 1 "valid" 0 "not valid" ;
VAL_ 533 ABS_WheelPulse_RR_Valid 1 "valid" 0 "not valid" ;
VAL_ 579 ESP_YawrateValue_valid 1 "invalid" 0 "valid" ;
VAL_ 579 ESP_LongAccSensorValid 1 "invalid" 0 "valid" ;
VAL_ 579 ESP_LaterAccSensorValid 1 "invalid" 0 "valid" ;
VAL_ 579 ESP_AEB_Available 1 "Available" 0 "Not available" ;
VAL_ 579 ESP_AEB_Intervention 1 "Active" 0 "Not active" ;
VAL_ 580 ESP_AWB_Available 1 "Available" 0 "Not available" ;
VAL_ 580 ESP_AWB_Intervention 1 "Active" 0 "Not active" ;
VAL_ 580 ESP_ABA_Available 1 "Available" 0 "Not available" ;
VAL_ 580 ESP_ABA_Intervention 1 "Active" 0 "Not active" ;
VAL_ 580 ESP_ABP_Available 1 "Available" 0 "Not available" ;
VAL_ 580 ESP_ABP_Intervention 1 "Active" 0 "Not active" ;
VAL_ 580 ESP_VirtualGaspadelPosReq 1 "Request" 0 "No Request" ;
VAL_ 580 ESC_CDPIntervention 1 "Active" 0 "Not Active" ;
VAL_ 580 ESC_CDPErrorSt 1 "Available" 0 "Not available" ;
VAL_ 624 APS_APAFailed 1 "APA Failure" 0 "Normal" ;
VAL_ 624 APS_CmdEPSSts 3 "Reserved" 2 "EPS control active" 1 "Control EPS request" 0 "No request" ;
VAL_ 625 APS_AutoSearchSts 7 "find out only slot-R" 6 "find out only slot-L" 5 "wait for vehicle driver confirm park" 4 "find out slot-Both，and “P” on R side" 3 "wait for vehicle slow down" 2 "find out slot-Both，and “P” on L side" 1 "slot searching" 0 "not in search mode" ;
VAL_ 625 APS_ParkOutChkResult 1 "OK" 0 "NOK" ;
VAL_ 625 APS_SuspendedReason 7 "EPB locked" 6 "seat belt released" 5 "mirror fold" 4 "trunk open" 3 "any door open" 2 "obstacle on path" 1 "VoiceSuspended" 0 "not suspended" ;
VAL_ 625 APS_AbortReason 31 "Reserved" 30 "Reserved" 29 "Reserved" 28 "Reserved" 27 "Reserved" 26 "Interrupt number over threshold" 25 "Current step number over threshold" 24 "APS time out" 23 "Vehicle speed over threshold" 22 "vehicle driver mode" 21 "ACC or ICC active" 20 "ESC active (ABS, TCS, ESP)" 19 "SAS not calibrated" 18 "invalid lateral accel signal" 17 "invalid longi accel signal" 16 "invalid yaw rate signal" 15 "invalid brake pedal switch state 预留" 14 "invalid vehicle speed" 13 "invalid wheel pulse counter signal" 12 "invalid wheel speed signal" 11 "invalid accel pedal position 预留" 10 "engine off  预留" 9 "APS internal failure (ECU hw)" 8 "VoiceExit" 7 "SAS failure" 6 "EMS failure  预留" 5 "PAS failure  预留" 4 "ACU failure 预留" 3 "TCU failure 预留" 2 "ESC failure" 1 "EPS failure" 0 "No fault" ;
VAL_ 625 APS_CurrentParkType 7 "reserved" 6 "reserved" 5 "reserved" 4 "mechanical garage" 3 "diagonal" 2 "parallel" 1 "perpendicular" 0 "not selected" ;
VAL_ 625 APS_OverrideReason 7 "Reserved" 6 "Reserved" 5 "Reserved" 4 "Overrode by EPB" 3 "overrode by gear shift" 2 "overrode by vehicle speed" 1 "overrode by steer" 0 "not overrode" ;
VAL_ 625 APS_VehicleDirection 3 "reserved" 2 "backward" 1 "forward" 0 "stopped" ;
VAL_ 625 APS_TerminatedType 3 "abort" 2 "suspended" 1 "driver override" 0 "not Terminated" ;
VAL_ 625 APS_ParkOutSystemStatus 1 "Normal" 0 "Judging" ;
VAL_ 625 APS_RemoteParkIn_Status 7 "RemoteParkOut_Error  由于HU TBOX产生的故障  具体故障见APS_RemotePark_Error_Status" 6 "RemoteParkIn_Exit  非HU TBOX原因导致的退出  具体故障见APS_AVM_AbortReason" 5 "RemoteParkIn_Complete" 4 "RemoteParkIn_Suspended  泊车按键松开暂停  其他暂停原因见APS_AVM_SuspendedReason" 3 "RemoteParkIn_Parking" 2 "RemoteParkIn_Start" 1 "Standy" 0 "Default" ;
VAL_ 625 APS_RemoteParkInResp 1 "Active" 0 "NoActive" ;
VAL_ 625 APS_BCM_RemoteParkIn_Status 1 "Active" 0 "NoActive" ;
VAL_ 625 APS_BCM_DoubleFlash 1 "Active" 0 "default" ;
VAL_ 625 APS_BCM_AllDoorUnLock_Door 1 "Active" 0 "default" ;
VAL_ 625 APS_RemoteParkOutResp 1 "Active" 0 "NoActive" ;
VAL_ 625 APS_BCM_PowerOffReq 1 "请求BCM下电" 0 "Default" ;
VAL_ 625 APS_RemotePark_Error_Status 7 "Reserved" 6 "RemoteParkOut_APS_TBOX_Start_TimeOut" 5 "RemoteParkOut_APS_TBOX_Request_Timeout" 4 "RemoteParkIn_APS_TBOX_Start_TimeOut" 3 "RemoteParkIn_APS_TBOX_Request_Timeout" 2 "RemoteParkIn_APS_TBOXConnectAPP_Timeout" 1 "RemoteParkIn_APS_HU_Request_Timeout" 0 "Default" ;
VAL_ 642 SCM_PRND_req 7 "Invalid" 6 "Reserved" 5 "Reserved" 4 "D" 3 "N" 2 "R" 1 "P" 0 "Default" ;
VAL_ 674 HU_APS_Audio_Active 1 "active" 0 "incative" ;
VAL_ 674 HU_Audio_AP_Request 7 "Reserved" 6 "确认泊出" 5 "遥控泊入" 4 "自动泊入" 3 "水平泊出" 2 "自选泊车" 1 "自动泊车" 0 "Default" ;
VAL_ 674 HU_Audio_Request_Command 15 "Reserved" 14 "Reserved" 13 "退出泊车" 12 "暂停" 11 "继续泊车" 10 "10" 9 "9" 8 "8" 7 "7" 6 "6" 5 "5" 4 "4" 3 "3" 2 "2" 1 "1" 0 "Default" ;
VAL_ 674 HU_AVM_ViewModeSwitch 3 "Reversed" 2 "View Mode Switch To HalfScreen" 1 "View Mode Switch To SoftKey" 0 "Default" ;
VAL_ 674 HU_Display_Mode_APA 3 "night" 2 "day" 1 "auto" 0 "default" ;
VAL_ 784 BCM_SystemPowerMode 3 "Ready" 2 "ON" 1 "reserved" 0 "OFF" ;
VAL_ 784 BCM_DriverLock_Sts 3 "Invalid" 2 "Lock" 1 "Unlock" 0 "Default" ;
VAL_ 784 BCM_PositionLight_Sts 1 "ON" 0 "OFF" ;
VAL_ 784 BCM_TurnLeftLight_Sts 1 "ON" 0 "OFF" ;
VAL_ 784 BCM_TurnRightLight_Sts 1 "ON" 0 "OFF" ;
VAL_ 784 BCM_HighBeam_Sts 1 "ON" 0 "OFF" ;
VAL_ 784 BCM_LowBeam_Sts 1 "ON" 0 "OFF" ;
VAL_ 784 BCM_HazardLight_Sts 1 "ON" 0 "OFF" ;
VAL_ 784 BCM_FL_Door_Sts 3 "Invalid" 2 "Close" 1 "Open" 0 "Default" ;
VAL_ 784 BCM_FR_Door_Sts 3 "Invalid" 2 "Close" 1 "Open" 0 "Default" ;
VAL_ 784 BCM_RL_Door_Sts 3 "Invalid" 2 "Close" 1 "Open" 0 "Default" ;
VAL_ 784 BCM_RR_Door_Sts 3 "Invalid" 2 "Close" 1 "Open" 0 "Default" ;
VAL_ 784 BCM_Trunk_Door_Sts 3 "Invalid" 2 "Close" 1 "Open" 0 "Default" ;
VAL_ 784 BCM_RearViewFoldSts 1 "展开" 0 "折叠" ;
VAL_ 928 ICM_DisPlayVehicleSpeed 4095 "Invalid" ;
